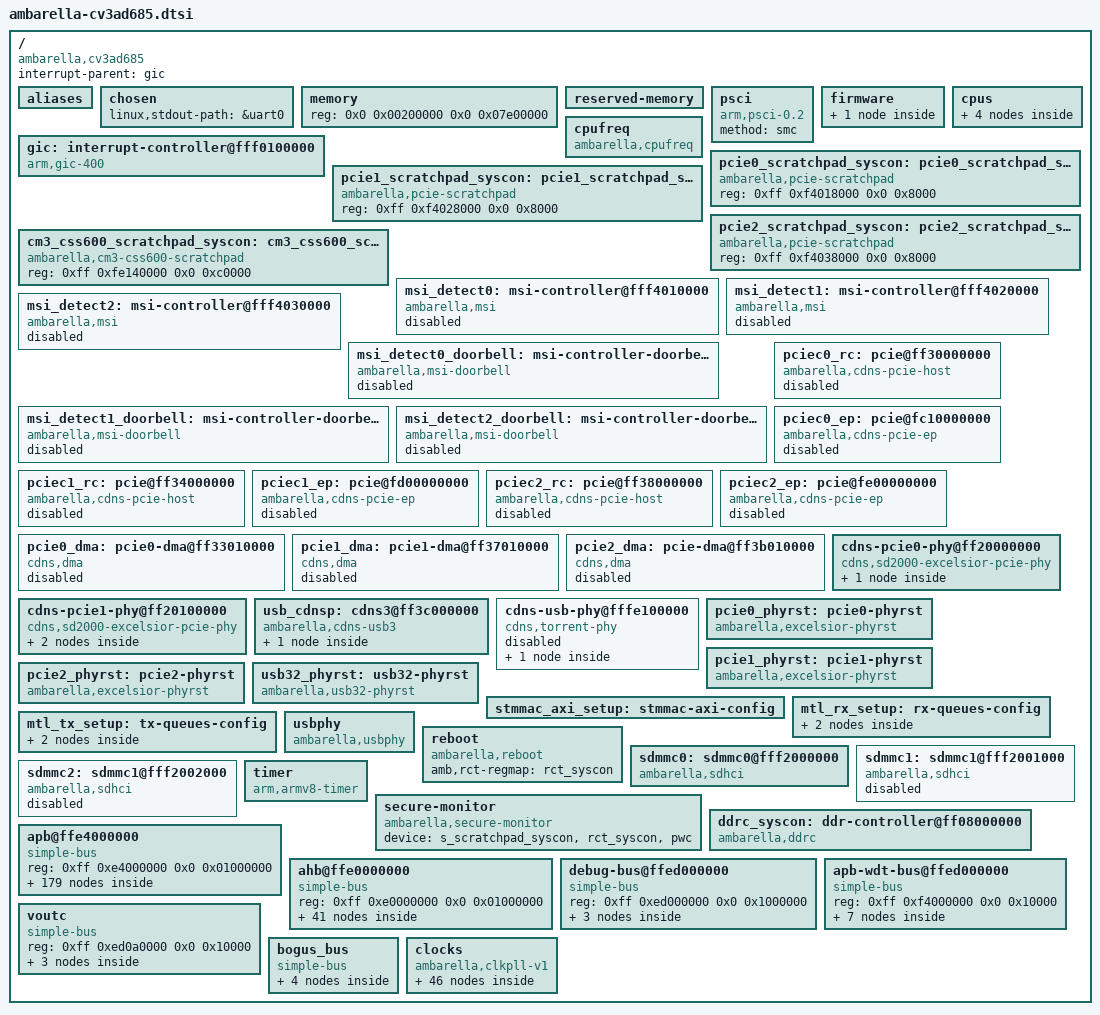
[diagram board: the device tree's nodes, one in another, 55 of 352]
/*
 * Copyright (C) 2013 Ambarella,Inc. - http://www.ambarella.com/
 * Author: Cao Rongrong <rrcao@ambarella.com>
 *
 * This program is free software; you can redistribute it and/or modify
 * it under the terms of the GNU General Public License version 2 as
 * published by the Free Software Foundation.
 */

/ {
	compatible = "ambarella,cv3ad685";
	interrupt-parent = <&gic>;
	#address-cells = <2>;
	#size-cells = <2>;

	aliases {
		serial0 = &uart0;
		serial1 = &uart1;
		serial2 = &uart2;
		serial3 = &uart3;
		serial4 = &uart4;
		nand = &nand0;
		sd0 = &sdmmc0;
		sd1 = &sdmmc1;
		sd2 = &sdmmc2;
		mmc0 = &sdmmc0;
		mmc1 = &sdmmc1;
		mmc2 = &sdmmc2;
		spinor = &spinor0;
		i2c0 = &i2c0;
		i2c1 = &i2c1;
		i2c2 = &i2c2;
		i2c3 = &i2c3;
		i2c4 = &i2c4;
		i2c5 = &i2c5;
		i2c6 = &i2c6;
		i2c7 = &i2c7;
		i2c8 = &i2c8;
		i2cs = &i2cs;
		spi0 = &spi0;
		spi1 = &spi1;
		spi2 = &spi2;
		spi3 = &spi3;
		spi4 = &spi4;
		spi5 = &spi5;
		spi6 = &spi6;
		spi7 = &spi7;
		ethernet0 = &mac0;
		ethernet1 = &mac1;
		ethernet2 = &mac2;
		dma0 = &dma0;
		dma1 = &dma1;
		dma2 = &dma2;
	};

	chosen: chosen {
		linux,stdout-path = &uart0;
	};

	/*
	 * the memory node will be overwritten in Amboot,
	 * here is just the default value.
	 */
	memory {
		device_type = "memory";
		reg = <0x0 0x00200000 0x0 0x07e00000>; /* 126M */
	};

	reserved-memory {
		#address-cells = <2>;
		#size-cells = <2>;
		ranges;
	};

	psci {
		compatible = "arm,psci-0.2";
		method = "smc";
	};

	firmware {
		optee {
			compatible = "linaro,optee-tz";
			method = "smc";
		};
	};

/*
	pmu {
		compatible = "arm,cortex-a78-pmu";
		interrupts = <0 3 0x4>,
			     <0 4 0x4>;
	};
*/

	cpus {
		#address-cells = <1>;
		#size-cells = <0>;

		cpu@0 {
			compatible = "arm,cortex-a78", "arm,armv8";
			device_type = "cpu";
			reg = <0x000>;
			enable-method = "psci";
		};

		cpu@1 {
			compatible = "arm,cortex-a78", "arm,armv8";
			device_type = "cpu";
			reg = <0x100>;
			enable-method = "psci";
		};

		cpu@2 {
			compatible = "arm,cortex-a78", "arm,armv8";
			device_type = "cpu";
			reg = <0x200>;
			enable-method = "psci";
		};

		cpu@3 {
			compatible = "arm,cortex-a78", "arm,armv8";
			device_type = "cpu";
			reg = <0x300>;
			enable-method = "psci";
		};
	};

	cpufreq {
		compatible = "ambarella,cpufreq";

		/*
		 * MASK
		 * + --- + ----- + ----- +
		 * | bit |   1   |   0   |
		 * + --- + ----- + ----- +
		 * | clk |  CORE | CORTEX|
		 * + --- + ----- + ----- +
		 */
		cpufreq-mask = <1>;
		amb,timer-freq-adjust-off;
		clocks = <&gclk_cortex &gclk_core>;
		clock-names = "cortex_clk", "core_clk";
		clocks-frequency-cortex-core =
			<1008000  504000>,
			<816000  336000>,
			<600000  240000>;
	};

	gic: interrupt-controller@fff0100000 {
		compatible = "arm,gic-400";
		#interrupt-cells = <3>;
		#address-cells = <0>;
		#size-cells = <1>;
		interrupt-controller;
		reg = <0xff 0xf0101000 0x0 0x1000>,	/* GIC Dist */
		      <0xff 0xf0102000 0x0 0x2000>,	/* GIC CPU */
		      /* following are not used if no virtulization */
		      <0xff 0xf0104000 0x0 0x2000>,	/* GIC VCPU Control */
		      <0xff 0xf0106000 0x0 0x2000>;	/* GIC VCPU */
		interrupts = <1 9 0xf04>;		/* GIC Maintenence IRQ */
	};

	pcie0_scratchpad_syscon: pcie0_scratchpad_syscon@fff4018000 {
		compatible = "ambarella,pcie-scratchpad", "syscon";
		reg = <0xff 0xf4018000 0x0 0x8000>;
	};

	pcie1_scratchpad_syscon: pcie1_scratchpad_syscon@fff4028000 {
		compatible = "ambarella,pcie-scratchpad", "syscon";
		reg = <0xff 0xf4028000 0x0 0x8000>;
	};

	pcie2_scratchpad_syscon: pcie2_scratchpad_syscon@fff4038000 {
		compatible = "ambarella,pcie-scratchpad", "syscon";
		reg = <0xff 0xf4038000 0x0 0x8000>;
	};

	cm3_css600_scratchpad_syscon: cm3_css600_scratchpad_syscon@fffe140000 {
		compatible = "ambarella,cm3-css600-scratchpad", "syscon";
		reg = <0xff 0xfe140000 0x0 0xc0000>;
	};

	msi_detect0: msi-controller@fff4010000 {
		compatible = "ambarella,msi";
		reg = <0xff 0xf4010000 0x0 0x08000>;
		msi-controller;
		msi-detection,spi-range = <257 4>;
		status = "disabled";
	};

	msi_detect1: msi-controller@fff4020000 {
		compatible = "ambarella,msi";
		reg = <0xff 0xf4020000 0x0 0x08000>;
		msi-controller;
		msi-detection,spi-range = <286 4>;
		status = "disabled";
	};

	msi_detect2: msi-controller@fff4030000 {
		compatible = "ambarella,msi";
		reg = <0xff 0xf4030000 0x0 0x08000>;
		msi-controller;
		msi-detection,spi-range = <315 4>;
		status = "disabled";
	};

	msi_detect0_doorbell: msi-controller-doorbell@fff4010000 {
		compatible = "ambarella,msi-doorbell";
		reg = <0xff 0xf4010000 0x0 0x08000>;
		msi-controller;
		msi-detection,spi-range = <257 4>;
		status = "disabled";
	};

	msi_detect1_doorbell: msi-controller-doorbell@fff4020000 {
		compatible = "ambarella,msi-doorbell";
		reg = <0xff 0xf4020000 0x0 0x08000>;
		msi-controller;
		msi-detection,spi-range = <286 4>;
		status = "disabled";
	};

	msi_detect2_doorbell: msi-controller-doorbell@fff4030000 {
		compatible = "ambarella,msi-doorbell";
		reg = <0xff 0xf4030000 0x0 0x08000>;
		msi-controller;
		msi-detection,spi-range = <315 4>;
		status = "disabled";
	};

	pciec0_rc: pcie@ff30000000 {
		compatible = "ambarella,cdns-pcie-host";
		device_type = "pci";
		#address-cells = <3>;
		#size-cells = <2>;
		#interrupt-cells = <1>;
		bus-range = <0 15>;
		linux,pci-domain = <0>;

		reg = <0xff 0x30000000 0x0 0x03006000>,
		      <0xfc 0x00000000 0x0 0x00100000>;	/* RC only */
		reg-names = "reg", "cfg";

		/*
		 * type: 0x01000000 IO
		 * type: 0x02000000 32bit mem space No prefetch
		 * type: 0x03000000 64bit mem space No prefetch
		 * type: 0x43000000 64bit mem space prefetch
		 */
		ranges = <0x02000000 0x00 0x00000000 0xfc 0x11000000 0x00 0x01000000>,
			 <0x43000000 0xfc 0x12000000 0xfc 0x12000000 0x00 0x08000000>;

		interrupt-map-mask = <0x00 0x0 0x0 0x7>;
		interrupt-map = <0x0 0x0 0x0 0x1 &gic 0 253 0x4>,
				<0x0 0x0 0x0 0x2 &gic 0 254 0x4>,
				<0x0 0x0 0x0 0x3 &gic 0 255 0x4>,
				<0x0 0x0 0x0 0x4 &gic 0 256 0x4>;

		cdns,no-bar-match-nbits = <40>;
		msi-parent = <&msi_detect0>;

		amb,scr-regmap = <&pcie0_scratchpad_syscon 0x14>;
		phys = <&pcie0_phy>;
		phy-names="pcie-phy";
		/* May be override by dts" */
		status = "disabled";
	};

	pciec0_ep: pcie@fc10000000 {
		compatible = "ambarella,cdns-pcie-ep";
		reg = <0xff 0x30000000 0x0 0x03020000>,
		      <0xfc 0x10000000 0x1 0x00000000>;
		reg-names = "reg", "mem";
		device_type = "pci-endpoint";

		cdns,max-outbound-regions = <8>;
		max-functions = /bits/ 8 <1>;

		amb,scr-regmap = <&pcie0_scratchpad_syscon 0x14>;
		phys = <&pcie0_phy>;
		phy-names="pcie-phy";
		msi-parent = <&msi_detect0_doorbell>;
		/* May be override by dts */
		status = "disabled";
	};

	pciec1_rc: pcie@ff34000000 {
		compatible = "ambarella,cdns-pcie-host";
		reg = <0xff 0x34000000 0x0 0x03006000>,
		      <0xfd 0x40000000 0x0 0x00100000>;
		reg-names = "reg", "cfg";
		device_type = "pci";
		#address-cells = <3>;
		#size-cells = <2>;
		#interrupt-cells = <1>;
		bus-range = <0 15>;
		linux,pci-domain = <1>;

		ranges = <0x02000000 0x00 0x00000000 0xfd 0x51000000 0x00 0x01000000>,
			 <0x43000000 0xfd 0x52000000 0xfd 0x52000000 0x00 0x08000000>;

		interrupt-map-mask = <0x00 0x0 0x0 0x7>;
		interrupt-map = <0x0 0x0 0x0 0x1 &gic 0 282 0x4>,
				<0x0 0x0 0x0 0x2 &gic 0 283 0x4>,
				<0x0 0x0 0x0 0x3 &gic 0 284 0x4>,
				<0x0 0x0 0x0 0x4 &gic 0 285 0x4>;

		cdns,no-bar-match-nbits = <40>;
		msi-parent = <&msi_detect0>;

		amb,scr-regmap = <&pcie1_scratchpad_syscon 0x14>;
		phys = <&pcie1_ln0_phy>;
		phy-names="pcie-phy";

		/* May be override by dts" */
		status = "disabled";
	};

	pciec1_ep: pcie@fd00000000 {
		compatible = "ambarella,cdns-pcie-ep";
		reg = <0xff 0x34000000 0x0 0x03020000>,
		      <0xfd 0x40000000 0x0 0x10000000>;
		reg-names = "reg", "mem";
		device_type = "pci-endpoint";

		cdns,max-outbound-regions = <8>;	/* EP only */
		max-functions = /bits/ 8 <1>;		/* EP only */

		amb,scr-regmap = <&pcie1_scratchpad_syscon 0x14>;
		phys = <&pcie1_ln0_phy>;
		phy-names="pcie-phy";
		msi-parent = <&msi_detect1_doorbell>;

		/* May be override by dts" */
		status = "disabled";
	};

	pciec2_rc: pcie@ff38000000 {
		compatible = "ambarella,cdns-pcie-host";
		reg = <0xff 0x38000000 0x0 0x03006000>,
		     <0xfe 0x40000000 0x0 0x00200000>;
		reg-names = "reg", "cfg";
		device_type = "pci";
		#address-cells = <3>;
		#size-cells = <2>;
		#interrupt-cells = <1>;
		bus-range = <0 15>;
		linux,pci-domain = <2>;

		/*
		* RC only, May be override by dts"
		*
		* type: 0x01000000 IO
		* type: 0x02000000 32bit mem space No prefetch
		* type: 0x03000000 64bit mem space No prefetch
		* type: 0x43000000 64bit mem space prefetch
		*/
		ranges = <0x02000000 0x00 0x00000000 0xfe 0x91000000 0x00 0x01000000>,
			 <0x43000000 0xfe 0x92000000 0xfe 0x92000000 0x00 0x08000000>;

		interrupt-map-mask = <0x00 0x0 0x0 0x7>;
		interrupt-map = <0x0 0x0 0x0 0x1 &gic 0 311 0x4>,
				<0x0 0x0 0x0 0x2 &gic 0 312 0x4>,
				<0x0 0x0 0x0 0x3 &gic 0 313 0x4>,
				<0x0 0x0 0x0 0x4 &gic 0 314 0x4>;

		cdns,no-bar-match-nbits = <40>;
		msi-parent = <&msi_detect0>;

		amb,scr-regmap = <&pcie2_scratchpad_syscon 0x14>;
		phys = <&pcie1_ln1_phy>;
		phy-names="pcie-phy";
		/* May be override by dts" */
		status = "disabled";
	};

	pciec2_ep: pcie@fe00000000 {
		compatible = "ambarella,cdns-pcie-ep";
		reg = <0xff 0x38000000 0x0 0x03020000>,
		     <0xfe 0x40000000 0x0 0x10000000>;
		reg-names = "reg", "mem";
		device_type = "pci-endpoint";

		cdns,max-outbound-regions = <8>;	/* EP only */
		max-functions = /bits/ 8 <1>;		/* EP only */

		amb,scr-regmap = <&pcie2_scratchpad_syscon 0x14>;
		phys = <&pcie1_ln1_phy>;
		phy-names="pcie-phy";
		msi-parent = <&msi_detect2_doorbell>;
		/* May be override by dts" */
		status = "disabled";
	};

	pcie0_dma: pcie0-dma@ff33010000 {
		compatible = "cdns,dma";
		reg = <0xff 0x33010000 0x0 0x00010000>;
		interrupts = <0 249 0x1>, <0 250 0x1>, <0 251 0x1>, <0 252 0x1>;
		/* May be override by dts */
		status = "disabled";
	};

	pcie1_dma: pcie1-dma@ff37010000 {
		compatible = "cdns,dma";
		reg = <0xff 0x37010000 0x0 0x00010000>;
		interrupts = <0 278 0x1>, <0 279 0x1>, <0 280 0x1>, <0 281 0x1>;
		/* May be override by dts */
		status = "disabled";
	};

	pcie2_dma: pcie-dma@ff3b010000 {
		compatible = "cdns,dma";
		reg = <0xff 0x3b010000 0x0 0x00010000>;
		interrupts = <0 307 0x1>, <0 308 0x1>, <0 309 0x1>, <0 310 0x1>;
		/* May be override by dts */
		status = "disabled";
	};

	/* This is a single-link PHY controller */
	cdns-pcie0-phy@ff20000000 {
		compatible = "cdns,sd2000-excelsior-pcie-phy";
		#address-cells = <1>;
		#size-cells = <0>;
		reg = <0xff 0x20000000 0x0 0x00100000>;

		resets = <&pcie0_phyrst 0>;
		reset-names = "phy_reset";

		clocks = <&cdns_phy_refclk>;
		clock-names = "refclk";

		pcie0_phy: phy@0 {
			reg = <0>;
			resets=<&pcie0_phyrst 2>;
			#phy-cells= <0>;
			cdns,num-lanes = <4>;
			cdns,ssc-mode = <0>;		// NO_SSC
			/* specify cdns,pcie-mode in dts, 1 is RC, 0 is EP */
			cdns,pcie-mode = <1>;
		};
	};

	/*
	 * This is a multi-link PHY controller, two lanes are assigned
	 * to two PCIe controllers seperately.
	 */
	cdns-pcie1-phy@ff20100000 {
		compatible = "cdns,sd2000-excelsior-pcie-phy";
		#address-cells = <1>;
		#size-cells = <0>;
		reg = <0xff 0x20100000 0x0 0x00100000>;

		resets = <&pcie1_phyrst 3>;
		reset-names = "phy_reset";

		clocks = <&cdns_phy_refclk>;
		clock-names = "refclk";

		pcie1_ln0_phy: phy@0 {
			reg = <0>;
			resets=<&pcie1_phyrst 5>;
			#phy-cells= <0>;
			cdns,num-lanes = <1>;
			cdns,ssc-mode = <0>;		// NO_SSC
			/* maybe override by dts, 1 is RC, 0 is EP */
			cdns,pcie-mode = <1>;
		};
		pcie1_ln1_phy: phy@1 {
			reg = <0>;
			resets=<&pcie2_phyrst 6>;
			#phy-cells= <0>;
			cdns,num-lanes = <1>;
			cdns,ssc-mode = <0>;		// NO_SSC
			/* maybe override by dts, 1 is RC, 0 is EP */
			cdns,pcie-mode = <0>;
		};
	};

	usb_cdnsp: cdns3@ff3c000000 {
		compatible = "ambarella,cdns-usb3";
		#address-cells = <2>;
		#size-cells = <2>;
		reg = <0xff 0x3c000000 0x0 0x1000000>;
		ranges;
		amb,scr-regmap = <&n_scratchpad_syscon>;
		amb,ocp-polarity = <1>;

		cdns3: cdns3 {
			compatible = "cdns,usb3";
			interrupts = <0 243 0x4>, <0 243 0x4>, <0 243 0x4>;
			interrupt-names = "host", "peripheral", "otg";
			reg = <0xff 0x3c008000 0x0 0x10000>,
			      <0xff 0x3c004000 0x0 0x4000>,
			      <0xff 0x3c000000 0x0 0x4000>;
			reg-names = "xhci", "dev", "otg";
			dr_mode = "otg";
			phys = <&usb32_phy>;
			phy-names = "cdns3,usb3-phy";
			maximum-speed = "super-speed-plus";
			usb-role-switch;
		};
	};

	cdns-usb-phy@fffe100000 {
		compatible = "cdns,torrent-phy";
		#address-cells = <1>;
		#size-cells = <0>;
		reg = <0xff 0xfe100000 0x0 0x00040000>;

		clocks = <&cdns_phy_refclk>;
		clock-names = "refclk";

		resets = <&usb32_phyrst 0>;
		reset-names = "torrent_reset";

		status = "disabled";

		usb32_phy: phy@0 {
			reg = <0>;
			resets = <&usb32_phyrst 1>;
			#phy-cells = <0>;
			cdns,phy-type = <4>;	/* TYPE_USB */
			cdns,num-lanes = <2>;
			cdns,ssc-mode = <2>;	/* INTERNAL_SSC */
		};
	};

	pcie0_phyrst: pcie0-phyrst {
		compatible = "ambarella,excelsior-phyrst";
		#reset-cells = <1>;
		amb,scr-regmap = <&n_scratchpad_syscon 0x180 0x190>;
		amb,pcie-scr-regmap = <&pcie0_scratchpad_syscon 0x4 0x8>;
		amb,pcie-controller = <&pciec0_rc>;
		amb,pcie-phy-id = <0>;
		amb,pcie-gen = <5>;
	};

	pcie1_phyrst: pcie1-phyrst {
		compatible = "ambarella,excelsior-phyrst";
		#reset-cells = <1>;
		amb,scr-regmap = <&n_scratchpad_syscon 0x184 0x190>;
		amb,pcie-scr-regmap = <&pcie1_scratchpad_syscon 0x4 0x8>;
		amb,pcie-controller = <&pciec1_rc>;
		amb,pcie-phy-id = <1>;
		amb,pcie-gen = <5>;
	};

	pcie2_phyrst: pcie2-phyrst {
		compatible = "ambarella,excelsior-phyrst";
		#reset-cells = <1>;
		amb,scr-regmap = <&n_scratchpad_syscon 0x184 0x190>;
		amb,pcie-scr-regmap = <&pcie2_scratchpad_syscon 0x4 0x8>;
		amb,pcie-controller = <&pciec2_ep>;
		amb,pcie-phy-id = <1>;
		amb,pcie-gen = <5>;
	};

	usb32_phyrst: usb32-phyrst {
		compatible = "ambarella,usb32-phyrst";
		#reset-cells = <1>;
		amb,scr-regmap = <&n_scratchpad_syscon 0x154 0x174 0x16c>;
	};


	stmmac_axi_setup: stmmac-axi-config {
		/* enable IS_ENABLED(CONFIG_ARCH_DMA_ADDR_T_64BIT) to enable 40bits dma
		   descriptor must be within 4GB.  buffer-addr can be 40bit
		 */
		snps,wr_osr_lmt = <0x3>;		/* cv3:max 8 Ref DMA_SysBus_Mode */
		snps,rd_osr_lmt = <0x3>;		/* cv3:max 8 Ref DMA_SysBus_Mode */
		snps,blen = <256 128 64 32 0 0 0>;	/* when FB=0,last 3 item has no mean */
	};

	/* at least two different queues to enable FPE features */
	mtl_rx_setup: rx-queues-config {
		snps,rx-queues-to-use = <2>;
		snps,rx-sched-sp;

		queue0 {
			snps,dcb-algorithm;
			snps,route-multi-broad;
			snps,map-to-dma-channel = <0x0>;
			snps,priority = <0x0>;
		};
		queue1 {
			snps,avb-algorithm;
			snps,route-avcp;
			snps,map-to-dma-channel = <0x1>;
			snps,priority = <0x1>;
		};
	};

	mtl_tx_setup: tx-queues-config {
		snps,tx-queues-to-use = <2>;
		snps,tx-sched-sp;

		queue0 {
			snps,dcb-algorithm;
			snps,weight = <0x10>;
			snps,priority = <0x0>;
		};
		queue1 {
			snps,avb-algorithm;
			snps,send_slope = <0x1000>;
			snps,idle_slope = <0x1000>;
			snps,high_credit = <0x04000000>; /* assume AVBframe = 8192 (8192*8*1024) */
			snps,low_credit = <0x18000000>;	 /* assume AVBframe = 8192 (8192*2*8*1024) of 2complete */
			snps,priority = <0x1>;
		};
	};

	usbphy: usbphy {
		compatible = "ambarella,usbphy";
		amb,ana-regmap = <&rct_syscon 0x050>;
		amb,own-regmap = <&rct_syscon 0x2c0>;		/* TODO: no such register in RCT */
		amb,phy-regmap = <&n_scratchpad_syscon 0x118>;
		amb,pol-regmap = <&n_scratchpad_syscon 0x060>;	/* TODO: polarity is remvoed in CV5 */
		amb,host-phy-num = <1>;
		amb,ocp-polarity = <0>;
	};

	reboot {
		compatible = "ambarella,reboot";
		amb,rct-regmap = <&rct_syscon>;
	};

	sdmmc0: sdmmc0@fff2000000 {
		compatible = "ambarella,sdhci";
		reg = <0xff 0xf2000000 0x0 0x1000>;
		interrupts = <0 138 0x4>;
		clocks = <&gclk_sd0>;
		bus-width = <8>;
		cap-sdio-irq;
		cap-sd-highspeed;
		cap-mmc-highspeed;
		mmc-hs200-1_8v;
	};

	sdmmc1: sdmmc1@fff2001000 { /* SDIO0 */
		compatible = "ambarella,sdhci";
		reg = <0xff 0xf2001000 0x0 0x1000>;
		interrupts = <0 139 0x4>;
		clocks = <&gclk_sd1>;
		bus-width = <4>;
		cap-sdio-irq;
		cap-sd-highspeed;
		cap-mmc-highspeed;
		status = "disabled";
	};

	sdmmc2: sdmmc1@fff2002000 { /* SDIO1 */
		compatible = "ambarella,sdhci";
		reg = <0xff 0xf2002000 0x0 0x1000>;
		interrupts = <0 140 0x4>;
		clocks = <&gclk_sd2>;
		bus-width = <4>;
		cap-sdio-irq;
		cap-sd-highspeed;
		cap-mmc-highspeed;
		status = "disabled";
	};

	timer {
		compatible = "arm,armv8-timer";
		interrupts = <1 13 0xf08>,	/* Secure Phys IRQ */
			     <1 14 0xf08>,	/* Non-secure Phys IRQ */
			     <1 11 0xf08>,	/* Virt IRQ */
			     <1 10 0xf08>;	/* Hyp IRQ */
	};

	secure-monitor {
		compatible = "ambarella,secure-monitor";
		#address-cells = <1>;
		#size-cells = <0>;
		device = <&s_scratchpad_syscon &rct_syscon &pwc>;
	};

	ddrc_syscon:ddr-controller@ff08000000 {
		compatible = "ambarella,ddrc", "syscon";
		#address-cells = <1>;
		#size-cells = <1>;
		reg = <0xff 0x08000000 0x0 0x80000>;
		burst-size = <0>;		/* This property will be overwritten in AMBOOT. */
	};

	apb@ffe4000000 {
		compatible = "simple-bus";
		#address-cells = <1>;
		#size-cells = <1>;
		reg = <0xff 0xe4000000 0x0 0x01000000>;
		ranges = <0xe4000000 0xff 0xe4000000 0x01000000>;

		clocksource1: timer@e4004054 {	/* timer6 */
			compatible = "ambarella,clock-source";
			reg = <0xe4004054 0x10 0xe4004030 0x4>;
			interrupts = <0 158 0x1>;
			ctrl-offset = <20>; /* bit offset in timer-ctrl reg */
			clocks = <&gclk_apb>;
			status = "disabled";
		};

		clockevent1: timer@e4004064 {	/* timer7, timer8, timer9, timer10 */
			compatible = "ambarella,local-clock-event";
			reg = <0xe4004064 0x10 0xe4004030 0x4>,
			      <0xe4004074 0x10 0xe4004030 0x4>,
			      <0xe4004088 0x10 0xe4004084 0x4>,
			      <0xe4004098 0x10 0xe4004084 0x4>;
			interrupts = <0 159 0x1>, <0 160 0x1>, <0 161 0x1>, <0 162 0x1>;
			ctrl-offset = <24 28 00 04>; /* bit offset in timer-ctrl reg */
			clocks = <&gclk_apb>;
			status = "disabled";
		};

		clocksource2: timer@e4005054 {	/* timer16 */
			compatible = "ambarella,clock-source";
			reg = <0xe4005054 0x10 0xe4005030 0x4>;
			interrupts = <0 168 0x1>;
			ctrl-offset = <20>; /* bit offset in timer-ctrl reg */
			clocks = <&gclk_apb>;
			status = "disabled";
		};

		clockevent2: timer@e4005064 {	/* timer17, timer18, timer19, timer20 */
			compatible = "ambarella,local-clock-event";
			reg = <0xe4005064 0x10 0xe4005030 0x4>,
			      <0xe4005074 0x10 0xe4005030 0x4>,
			      <0xe4005088 0x10 0xe4005084 0x4>,
			      <0xe4005098 0x10 0xe4005084 0x4>;
			interrupts = <0 169 0x1>, <0 170 0x1>, <0 171 0x1>, <0 172 0x1>;
			ctrl-offset = <24 28 00 04>; /* bit offset in timer-ctrl reg */
			clocks = <&gclk_apb>;
			status = "disabled";
		};

		clocksource3: timer@e4006054 {	/* timer26 */
			compatible = "ambarella,clock-source";
			reg = <0xe4006054 0x10 0xe4006030 0x4>;
			interrupts = <0 464 0x1>;
			ctrl-offset = <20>; /* bit offset in timer-ctrl reg */
			clocks = <&gclk_apb>;
			status = "disabled";
		};

		clockevent3: timer@e4006044 {	/* timer27, timer28, timer29, timer30 */
			compatible = "ambarella,local-clock-event";
			reg = <0xe4006064 0x10 0xe4006030 0x4>,
			      <0xe4006074 0x10 0xe4006030 0x4>,
			      <0xe4006088 0x10 0xe4006084 0x4>,
			      <0xe4006098 0x10 0xe4006084 0x4>;
			interrupts = <0 465 0x1>, <0 466 0x1>, <0 467 0x1>, <0 468 0x1>;
			ctrl-offset = <24 28 00 04>; /* bit offset in timer-ctrl reg */
			clocks = <&gclk_apb>;
			status = "disabled";
		};

		uart0: uart@e4000000 {
			compatible = "ambarella,uart";
			reg = <0xe4000000 0x1000>;
			interrupts = <0 241 0x4>;
			pinctrl-names = "default";
			pinctrl-0 = <&uart0_pins>;
			clocks = <&gclk_uart0>;
			status = "ok";
		};

		ir@e4001000 {
			compatible = "ambarella,ir";
			reg = <0xe4001000 0x1000>;
			interrupts = <0 242 0x4>;
			pinctrl-names = "default";
			pinctrl-0 = <&ir_pins_a>;
			clocks = <&gclk_ir>;
			status = "disabled";
		};

		i2c0: i2c@e4008000 {
			compatible = "ambarella,i2c";
			#address-cells = <1>;
			#size-cells = <0>;
			reg = <0xe4008000 0x1000>;
			interrupts = <0 214 0x4>;
			pinctrl-names = "default";
			pinctrl-0 = <&i2c0_pins_a>;
			clocks = <&gclk_apb>;
			clock-frequency = <100000>;
			amb,i2c-class = <0x81>;
			status = "disabled";
		};

		i2c1: i2c@e4009000 {
			compatible = "ambarella,i2c";
			#address-cells = <1>;
			#size-cells = <0>;
			reg = <0xe4009000 0x1000>;
			interrupts = <0 215 0x4>;
			pinctrl-names = "default";
			pinctrl-0 = <&i2c1_pins_a>;
			clocks = <&gclk_apb>;
			clock-frequency = <100000>;
			amb,i2c-class = <0x08>;
			status = "disabled";
		};

		i2c2: i2c@e400a000 {
			compatible = "ambarella,i2c";
			#address-cells = <1>;
			#size-cells = <0>;
			reg = <0xe400a000 0x1000>;
			interrupts = <0 216 0x4>;
			clocks = <&gclk_apb>;
			pinctrl-names = "default";
			pinctrl-0 = <&i2c2_pins_a>;
			clock-frequency = <100000>;
			amb,i2c-class = <0x81>;
			status = "disabled";
		};

		i2c3: i2c@e400b000 {
			compatible = "ambarella,i2c";
			#address-cells = <1>;
			#size-cells = <0>;
			reg = <0xe400b000 0x1000>;
			interrupts = <0 217 0x4>;
			clocks = <&gclk_apb>;
			pinctrl-names = "default";
			pinctrl-0 = <&i2c3_pins_a>;
			clock-frequency = <100000>;
			amb,i2c-class = <0x81>;
			status = "disabled";
		};

		i2c4: i2c@e400e000 {
			compatible = "ambarella,i2c";
			#address-cells = <1>;
			#size-cells = <0>;
			reg = <0xe400e000 0x1000>;
			interrupts = <0 218 0x4>;
			clocks = <&gclk_apb>;
			pinctrl-names = "default";
			pinctrl-0 = <&i2c4_pins_a>;
			clock-frequency = <100000>;
			amb,i2c-class = <0x81>;
			status = "disabled";
		};

		i2c5: i2c@e400f000 {
			compatible = "ambarella,i2c";
			#address-cells = <1>;
			#size-cells = <0>;
			reg = <0xe400f000 0x1000>;
			interrupts = <0 219 0x4>;
			clocks = <&gclk_apb>;
			pinctrl-names = "default";
			pinctrl-0 = <&i2c5_pins_a>;
			clock-frequency = <100000>;
			amb,i2c-class = <0x81>;
			status = "disabled";
		};

		i2c6: i2c@e401c000 {
			compatible = "ambarella,i2c";
			#address-cells = <1>;
			#size-cells = <0>;
			reg = <0xe401c000 0x1000>;
			interrupts = <0 220 0x4>;
			clocks = <&gclk_apb>;
			pinctrl-names = "default";
			pinctrl-0 = <&i2c6_pins_a>;
			clock-frequency = <100000>;
			amb,i2c-class = <0x81>;
			status = "disabled";
		};

		i2c7: i2c@e401d000 {
			compatible = "ambarella,i2c";
			#address-cells = <1>;
			#size-cells = <0>;
			reg = <0xe401d000 0x1000>;
			interrupts = <0 221 0x4>;
			clocks = <&gclk_apb>;
			pinctrl-names = "default";
			pinctrl-0 = <&i2c7_pins_a>;
			clock-frequency = <100000>;
			amb,i2c-class = <0x81>;
			status = "disabled";
		};

		i2c8: i2c@e401e000 {
			compatible = "ambarella,i2c";
			#address-cells = <1>;
			#size-cells = <0>;
			reg = <0xe401e000 0x1000>;
			interrupts = <0 222 0x4>;
			clocks = <&gclk_apb>;
			pinctrl-names = "default";
			pinctrl-0 = <&i2c8_pins_a>;
			clock-frequency = <100000>;
			amb,i2c-class = <0x81>;
			status = "disabled";
		};

		i2cs: i2cs@e4007000 {
			compatible = "ambarella,i2cs";
			#address-cells = <1>;
			#size-cells = <0>;
			reg = <0xe4007000 0x1000>;
			interrupts = <0 223 0x4>;
			clocks = <&gclk_apb>;
			pinctrl-names = "default";
			pinctrl-0 = <&i2cs0_pins>;
			status = "disabled";
		};

		pwm0: pwm@e4003000 {
			compatible = "ambarella,pwm";
			reg = <0xe4003000 0x1000>;
			clock-frequency = <2000000>;
			clocks = <&gclk_pwm>;
			#pwm-cells = <3>;
		};

		pwm1: pwm@e400c000 {
			compatible = "ambarella,pwm";
			reg = <0xe400c000 0x1000>;
			clock-frequency = <2000000>;
			clocks = <&gclk_pwm>;
			#pwm-cells = <3>;
		};

		pwm2: pwm@e400d000 {
			compatible = "ambarella,pwm";
			reg = <0xe400d000 0x1000>;
			clock-frequency = <2000000>;
			clocks = <&gclk_pwm>;
			#pwm-cells = <3>;
		};

		pinctrl: pinctrl@e4010000 {
			compatible = "ambarella,pinctrl";
			#address-cells = <1>;
			#size-cells = <0>;
			reg = <0xe4013000 0x1000>,
			      <0xe4014000 0x1000>,
			      <0xe4015000 0x1000>,
			      <0xe4016000 0x1000>,
			      <0xe4017000 0x1000>,
			      <0xe4018000 0x1000>,
			      <0xe4019000 0x1000>,
			      <0xe4010000 0x1000>;
			reg-names = "gpio0", "gpio1", "gpio2", "gpio3", "gpio4", "gpio5", "gpio6", "iomux";
			interrupts = <0 224 0x4>, <0 225 0x4>, <0 226 0x4>, <0 227 0x4>,
				     <0 228 0x4>, <0 229 0x4>, <0 230 0x4>;
			amb,pull-regmap = <&s_scratchpad_syscon>;
			amb,ds-regmap = <&rct_syscon 0x314>;
			amb,secure-ctrl-bit = <50 51 52 53 54 59 37 48>;

			gpio: gpio@0 {
				reg = <0>;
				gpio-controller;
				#gpio-cells = <2>;
				gpio-ranges = <&pinctrl 0 0 213>;
				interrupt-controller;
				#interrupt-cells = <2>;
			};

			uart0_pins: uart0@0 {
				reg = <0>;
				amb,pinmux-ids = <0x104b 0x104c>;
			};

			uart1_pins_a: uart1@0 {		/* UART0_AHB_TX/RX */
				reg = <0>;
				amb,pinmux-ids = <0x2017 0x2018>;
			};

			uart1_pins_b: uart1@1 {
				reg = <1>;
				amb,pinmux-ids = <0x2027 0x2028>;
			};

			uart1_pins_c: uart1@2 {
				reg = <2>;
				amb,pinmux-ids = <0x3043 0x3047>;
			};

			uart1_pins_d: uart1@3 {
				reg = <3>;
				amb,pinmux-ids = <0x10ac 0x10ad>;
			};

			uart1_pins_e: uart1@4 {
				reg = <4>;
				amb,pinmux-ids = <0x30bc 0x30bd>;
			};

			uart1_flow_pins_a: uart1_flow@0 {
				reg = <0>;
				amb,pinmux-ids = <0x2019 0x201a>;
			};

			uart1_flow_pins_b: uart1_flow@1 {
				reg = <1>;
				amb,pinmux-ids = <0x2029 0x202a>;
			};

			uart1_flow_pins_c: uart1_flow@2 {
				reg = <2>;
				amb,pinmux-ids = <0x3045 0x3048>;
			};

			uart1_flow_pins_d: uart1_flow@3 {
				reg = <3>;
				amb,pinmux-ids = <0x10ae 0x10af>;
			};

			uart1_flow_pins_e: uart1_flow@4 {
				reg = <4>;
				amb,pinmux-ids = <0x30be 0x30bf>;
			};

			uart2_pins_a: uart2@0 {		/* UART1_AHB_RX/RX */
				reg = <0>;
				amb,pinmux-ids = <0x201b 0x201c>;
			};

			uart2_pins_b: uart2@1 {
				reg = <1>;
				amb,pinmux-ids = <0x202b 0x202c>;
			};

			uart2_pins_c: uart2@2 {
				reg = <2>;
				amb,pinmux-ids = <0x10b0 0x10b1>;
			};

			uart2_pins_d: uart2@3 {
				reg = <3>;
				amb,pinmux-ids = <0x30b8 0x30b9>;
			};

			uart2_flow_pins_a: uart2_flow@0 {
				reg = <0>;
				amb,pinmux-ids = <0x201d 0x201e>;
			};

			uart2_flow_pins_b: uart2_flow@1 {
				reg = <1>;
				amb,pinmux-ids = <0x202d 0x202e>;
			};

			uart2_flow_pins_c: uart2_flow@2 {
				reg = <2>;
				amb,pinmux-ids = <0x10b2 0x10b3>;
			};

			uart2_flow_pins_d: uart2_flow@3 {
				reg = <3>;
				amb,pinmux-ids = <0x30ba 0x30bb>;
			};

			uart3_pins_a: uart3@0 {		/* UART2_AHB_RX/RX */
				reg = <0>;
				amb,pinmux-ids = <0x201f 0x2020>;
			};

			uart3_pins_b: uart3@1 {
				reg = <1>;
				amb,pinmux-ids = <0x202f 0x2030>;
			};

			uart3_pins_c: uart3@2 {
				reg = <2>;
				amb,pinmux-ids = <0x10b4 0x10b5>;
			};

			uart3_pins_d: uart3@3 {
				reg = <3>;
				amb,pinmux-ids = <0x30c0 0x30c1>;
			};

			uart3_flow_pins_a: uart3_flow@0 {
				reg = <0>;
				amb,pinmux-ids = <0x2021 0x2022>;
			};

			uart3_flow_pins_b: uart3_flow@1 {
				reg = <1>;
				amb,pinmux-ids = <0x2031 0x2032>;
			};

			uart3_flow_pins_c: uart3_flow@2 {
				reg = <2>;
				amb,pinmux-ids = <0x10b6 0x10b7>;
			};

			uart3_flow_pins_d: uart3_flow@3 {
				reg = <3>;
				amb,pinmux-ids = <0x30c2 0x30c3>;
			};

			uart4_pins_a: uart4@0 {		/* UART3_AHB_RX/RX */
				reg = <0>;
				amb,pinmux-ids = <0x2023 0x2024>;
			};

			uart4_pins_b: uart4@1 {
				reg = <1>;
				amb,pinmux-ids = <0x2033 0x2034>;
			};

			uart4_pins_c: uart4@2 {
				reg = <2>;
				amb,pinmux-ids = <0x30b4 0x30b5>;
			};

			uart4_flow_pins_a: uart4_flow@0 {
				reg = <0>;
				amb,pinmux-ids = <0x2025 0x2026>;
			};

			uart4_flow_pins_b: uart4_flow@1 {
				reg = <1>;
				amb,pinmux-ids = <0x2035 0x2036>;
			};

			uart4_flow_pins_c: uart4_flow@2 {
				reg = <2>;
				amb,pinmux-ids = <0x30b6 0x30b7>;
			};

			snand_pins: snand@0 {
				reg = <0>;
				amb,pinmux-ids = <0x1087 0x1088 0x1089 0x108a
						  0x108b 0x108c>;
			};

			spinor_pins: spinor@0 {
				reg = <0>;
				amb,pinmux-ids = <0x108d 0x108e 0x108f 0x1090
						  0x1091 0x1092 0x1093 0x1094
						  0x1095 0x1096 0x1097>;
			};

			sdmmc0_reset_pin: sdmmc0_reset@0 {
				reg = <0>;
				amb,pinmux-ids = <0x109f>;
			};

			sdmmc1_reset_pin: sdmmc1_reset@0 {
				reg = <0>;
				amb,pinmux-ids = <0x10a1>;
			};

			sdmmc2_reset_pin: sdmmc2_reset@0 {
				reg = <0>;
				amb,pinmux-ids = <0x10a3>;
			};

			enet_ext_osc_clk: enet-ext-osc-clk@0 {	/* shared by enet0/1/2 125MHZ input refclock */
				reg = <0>;
				amb,pinmux-ids = <0x2067>;
			};

			enet_2nd_ref_clk_a: enet-2nd-ref-clk@0 {
				reg = <0>;
				amb,pinmux-ids = <0x1066>;
			};

			enet_2nd_ref_clk_b: enet-2nd-ref-clk@1 {
				reg = <1>;
				amb,pinmux-ids = <0x1068>;
			};

			enet_2nd_ref_clk_c: enet-2nd-ref-clk@2 {
				reg = <2>;
				amb,pinmux-ids = <0x2068>;
			};

			enet_2nd_ref_clk_d: enet-2nd-ref-clk@3 {
				reg = <3>;
				amb,pinmux-ids = <0x1077>;
			};

			rgmii0_pins: eth0@0 {	/* ethernet-mac0 && use mac-mdio */
				reg = <0>;
				amb,pinmux-ids = <0x2058 0x2059 0x205a 0x205b
						  0x205c 0x205d 0x205e 0x205f
						  0x2060 0x2061	0x2062 0x2063 /* eth-mdio */
						  0x2065 0x2066>;
			};

			rmii0_pins: eth0@1 {
				reg = <1>;
				amb,pinmux-ids = <0x1058 0x1059 0x105a 0x105d
						  0x105e 0x1061 0x1062 0x1063
						  0x1065>;
			};

			rgmii0_ptp_pps_o: enet0-ptp-pps-o@0 {
				reg = <0>;
				amb,pinmux-ids = <0x2064>;
			};

			rmii0_ptp_pps_o: enet0-ptp-pps-o@1 {
				reg = <1>;
				amb,pinmux-ids = <0x1064>;
			};

			rgmii1_pins: eth1@0 {	/* ethernet-mac1 */
				reg = <0>;
				amb,pinmux-ids = <0x2069 0x206a 0x206b 0x206c
						  0x206d 0x206e 0x206f 0x2070
						  0x2071 0x2072 0x2073 0x2074
						  0x2076 0x2077>;

			};

			rmii1_pins: eth1@1 {
				reg = <1>;
				amb,pinmux-ids = <0x1069 0x106a 0x106b 0x106e
						  0x106f 0x1072 0x2073 0x2074
						  0x1076>;
			};

			rgmii1_ptp_pps_o: enet1-ptp-pps-o@0 {
				reg = <0>;
				amb,pinmux-ids = <0x2075>;
			};

			rmii1_ptp_pps_o: enet1-ptp-pps-o@1 {
				reg = <1>;
				amb,pinmux-ids = <0x1075>;
			};

			rgmii2_pins: eth2@0 {	/* ethernet-mac2 */
				reg = <0>;
				amb,pinmux-ids = <0x2078 0x2079 0x207a 0x207b
						  0x207c 0x207d 0x207e 0x207f
						  0x2080 0x2081 0x2082 0x2083
						  0x2085 0x2086>;
			};

			rmii2_pins: eth2@1 {
				reg = <1>;
				amb,pinmux-ids = <0x1078 0x1079 0x107a 0x107d
						  0x107e 0x1081 0x1082 0x1083
						  0x1085>;
			};

			rgmii2_ptp_pps_o: enet2-ptp-pps-o@0 {
				reg = <0>;
				amb,pinmux-ids = <0x2084>;
			};

			rmii2_ptp_pps_o: enet2-ptp-pps-o@1 {
				reg = <1>;
				amb,pinmux-ids = <0x1084>;
			};

			i2c0_pins_a: i2c0@0 {
				reg = <0>;
				amb,pinmux-ids = <0x2002 0x2003>;
			};

			i2c0_pins_b: i2c0@1 {
				reg = <1>;
				amb,pinmux-ids = <0x1027 0x1028>;
			};

			i2c1_pins_a: i2c1@0 {
				reg = <0>;
				amb,pinmux-ids = <0x2004 0x2005>;
			};

			i2c1_pins_b: i2c1@1 {
				reg = <1>;
				amb,pinmux-ids = <0x1029 0x102a>;
			};

			i2c2_pins_a: i2c2@0 {
				reg = <0>;
				amb,pinmux-ids = <0x2007 0x2008>;
			};

			i2c2_pins_b: i2c2@1 {
				reg = <1>;
				amb,pinmux-ids = <0x102b 0x102c>;
			};

			i2c2_pins_c: i2c2@2 {
				reg = <2>;
				amb,pinmux-ids = <0x10a7 0x10a8>;
			};

			i2c3_pins_a: i2c3@0 {
				reg = <0>;
				amb,pinmux-ids = <0x2009 0x200a>;
			};

			i2c3_pins_b: i2c3@1 {
				reg = <1>;
				amb,pinmux-ids = <0x102d 0x102e>;
			};

			i2c4_pins_a: i2c4@0 {
				reg = <0>;
				amb,pinmux-ids = <0x200b 0x200c>;
			};

			i2c4_pins_b: i2c4@1 {
				reg = <1>;
				amb,pinmux-ids = <0x102f 0x1030>;
			};

			i2c5_pins_a: i2c5@0 {
				reg = <0>;
				amb,pinmux-ids = <0x200d 0x200e>;
			};

			i2c5_pins_b: i2c5@1 {
				reg = <1>;
				amb,pinmux-ids = <0x1031 0x1032>;
			};

			i2c6_pins_a: i2c6@0 {
				reg = <0>;
				amb,pinmux-ids = <0x200f 0x2010>;
			};

			i2c6_pins_b: i2c6@1 {
				reg = <1>;
				amb,pinmux-ids = <0x1033 0x1034>;
			};

			i2c7_pins_a: i2c7@0 {
				reg = <0>;
				amb,pinmux-ids = <0x2011 0x2012>;
			};

			i2c7_pins_b: i2c7@1 {
				reg = <1>;
				amb,pinmux-ids = <0x1035 0x1036>;
			};

			i2c8_pins_a: i2c8@0 {
				reg = <0>;
				amb,pinmux-ids = <0x2013 0x2014>;
			};

			i2c8_pins_b: i2c8@1 {
				reg = <1>;
				amb,pinmux-ids = <0x3033 0x3034>;
			};

			i2c8_pins_c: i2c8@2 {
				reg = <2>;
				amb,pinmux-ids = <0x1037 0x1038>;
			};

			i2cs0_pins: i2cs0@0 {
				reg = <0>;
				amb,pinmux-ids = <0x1039 0x103a>;
			};

			can0_pins_a: can0@0 {
				reg = <0>;
				amb,pinmux-ids = <0x10b8 0x10b9>;
			};

			can0_pins_b: can0@1 {
				reg = <1>;
				amb,pinmux-ids = <0x40ac 0x40ad>;
			};

			can1_pins_a: can1@0 {
				reg = <0>;
				amb,pinmux-ids = <0x10ba 0x10bb>;
			};

			can1_pins_b: can1@1 {
				reg = <1>;
				amb,pinmux-ids = <0x40ae 0x40af>;
			};

			can2_pins_a: can2@0 {
				reg = <0>;
				amb,pinmux-ids = <0x10bc 0x10bd>;
			};

			can2_pins_b: can2@1 {
				reg = <1>;
				amb,pinmux-ids = <0x40b0 0x40b1>;
			};

			can3_pins_a: can3@0 {
				reg = <0>;
				amb,pinmux-ids = <0x10be 0x10bf>;
			};

			can3_pins_b: can3@1 {
				reg = <1>;
				amb,pinmux-ids = <0x40b2 0x40b3>;
			};

			can4_pins_a: can4@0 {
				reg = <0>;
				amb,pinmux-ids = <0x10c0 0x10c1>;
			};

			can4_pins_b: can4@1 {
				reg = <1>;
				amb,pinmux-ids = <0x40b4 0x40b5>;
			};

			can5_pins_a: can5@0 {
				reg = <0>;
				amb,pinmux-ids = <0x10c2 0x10c3>;
			};

			can5_pins_b: can5@1 {
				reg = <1>;
				amb,pinmux-ids = <0x40b6 0x40b7>;
			};

			ir_pins_a: ir0@0 {
				reg = <0>;
				amb,pinmux-ids = <0x1000>;
			};

			ir_pins_b: ir0@1 {
				reg = <1>;
				amb,pinmux-ids = <0x30a6>;
			};

			wdt_pins_a: wdt0@0 {
				reg = <0>;
				amb,pinmux-ids = <0x2000>;
			};

			wdt_pins_b: wdt0@1 {
				reg = <1>;
				amb,pinmux-ids = <0x2001>;
			};

			wdt_pins_c: wdt0@2 {
				reg = <2>;
				amb,pinmux-ids = <0x2006>;
			};

			wdt_pins_d: wdt0@3 {
				reg = <3>;
				amb,pinmux-ids = <0x2015>;
			};

			wdt_pins_e: wdt0@4 {
				reg = <4>;
				amb,pinmux-ids = <0x20a9>;
			};

			wdt_pins_f: wdt0@5 {
				reg = <5>;
				amb,pinmux-ids = <0x30b3>;
			};

			i2s0_pins: i2s0@0 {
				reg = <0>;
				amb,pinmux-ids = <0x1050 0x1051 0x1052 0x1053>;
			};

			i2s1_pins: i2s1@0 {
				reg = <0>;
				amb,pinmux-ids = <0x1054 0x1055 0x1056 0x1057>;
			};

			dmic0_pins: dmic_pins@0 {
				reg = <0>;
				amb,pinmux-ids = <0x2050 0x2051>;
			};

			pwm0_pins_a: pwm0@0 {
				reg = <0>;
				amb,pinmux-ids = <0x3002>;
			};

			pwm0_pins_b: pwm0@1 {
				reg = <1>;
				amb,pinmux-ids = <0x3027>;
			};

			pwm0_pins_c: pwm0@2 {
				reg = <2>;
				amb,pinmux-ids = <0x203b>;
			};

			pwm0_pins_d: pwm0@3 {
				reg = <3>;
				amb,pinmux-ids = <0x104d>;
			};

			pwm1_pins_a: pwm1@0 {
				reg = <0>;
				amb,pinmux-ids = <0x3002>;
			};

			pwm1_pins_b: pwm1@1 {
				reg = <1>;
				amb,pinmux-ids = <0x3028>;
			};

			pwm1_pins_c: pwm1@2 {
				reg = <2>;
				amb,pinmux-ids = <0x203c>;
			};

			pwm1_pins_d: pwm1@3 {
				reg = <3>;
				amb,pinmux-ids = <0x104e>;
			};

			pwm2_pins_a: pwm2@0 {
				reg = <0>;
				amb,pinmux-ids = <0x3004>;
			};

			pwm2_pins_b: pwm2@1 {
				reg = <1>;
				amb,pinmux-ids = <0x3029>;
			};

			pwm2_pins_c: pwm2@2 {
				reg = <2>;
				amb,pinmux-ids = <0x203d>;
			};

			pwm2_pins_d: pwm2@3 {
				reg = <3>;
				amb,pinmux-ids = <0x104f>;
			};

			pwm3_pins_a: pwm3@0 {
				reg = <0>;
				amb,pinmux-ids = <0x3005>;
			};

			pwm3_pins_b: pwm3@1 {
				reg = <1>;
				amb,pinmux-ids = <0x302a>;
			};

			pwm3_pins_c: pwm3@2 {
				reg = <2>;
				amb,pinmux-ids = <0x203e>;
			};

			pwm4_pins_a: pwm4@0 {
				reg = <0>;
				amb,pinmux-ids = <0x3006>;
			};

			pwm4_pins_b: pwm4@1 {
				reg = <1>;
				amb,pinmux-ids = <0x302b>;
			};

			pwm4_pins_c: pwm4@2 {
				reg = <2>;
				amb,pinmux-ids = <0x203f>;
			};

			pwm5_pins_a: pwm5@0 {
				reg = <0>;
				amb,pinmux-ids = <0x3007>;
			};

			pwm5_pins_b: pwm5@1 {
				reg = <1>;
				amb,pinmux-ids = <0x302c>;
			};

			pwm5_pins_c: pwm5@2 {
				reg = <2>;
				amb,pinmux-ids = <0x2040>;
			};

			pwm6_pins_a: pwm6@0 {
				reg = <0>;
				amb,pinmux-ids = <0x3008>;
			};

			pwm6_pins_b: pwm6@1 {
				reg = <1>;
				amb,pinmux-ids = <0x302d>;
			};

			pwm6_pins_c: pwm6@2 {
				reg = <2>;
				amb,pinmux-ids = <0x2041>;
			};

			pwm7_pins_a: pwm7@0 {
				reg = <0>;
				amb,pinmux-ids = <0x3009>;
			};

			pwm7_pins_b: pwm7@1 {
				reg = <1>;
				amb,pinmux-ids = <0x302e>;
			};

			pwm7_pins_c: pwm7@2 {
				reg = <2>;
				amb,pinmux-ids = <0x2042>;
			};

			pwm8_pins_a: pwm8@0 {
				reg = <0>;
				amb,pinmux-ids = <0x300a>;
			};

			pwm8_pins_b: pwm8@1 {
				reg = <1>;
				amb,pinmux-ids = <0x302f>;
			};

			pwm8_pins_c: pwm8@2 {
				reg = <2>;
				amb,pinmux-ids = <0x2043>;
			};

			pwm9_pins_a: pwm9@0 {
				reg = <0>;
				amb,pinmux-ids = <0x300b>;
			};

			pwm9_pins_b: pwm9@1 {
				reg = <1>;
				amb,pinmux-ids = <0x3030>;
			};

			pwm9_pins_c: pwm9@2 {
				reg = <2>;
				amb,pinmux-ids = <0x2044>;
			};

			pwm10_pins_a: pwm10@0 {
				reg = <0>;
				amb,pinmux-ids = <0x300c>;
			};

			pwm10_pins_b: pwm10@1 {
				reg = <1>;
				amb,pinmux-ids = <0x3031>;
			};

			pwm10_pins_c: pwm10@2 {
				reg = <2>;
				amb,pinmux-ids = <0x2045>;
			};

			pwm11_pins_a: pwm11@0 {
				reg = <0>;
				amb,pinmux-ids = <0x300d>;
			};

			pwm11_pins_b: pwm11@1 {
				reg = <1>;
				amb,pinmux-ids = <0x3032>;
			};

			pwm11_pins_c: pwm11@2 {
				reg = <2>;
				amb,pinmux-ids = <0x2046>;
			};

			spi0_pins_a: spi0@0 {
				reg = <0>;
				amb,pinmux-ids = <0x1002 0x1003 0x1004>;
			};

			spi0_pins_b: spi0@1 {
				reg = <1>;
				amb,pinmux-ids = <0x3023 0x3024 0x3025>;
			};

			spi0_pins_c: spi0@2 {
				reg = <2>;
				amb,pinmux-ids = <0x20ac 0x20ad 0x20ae>;
			};

			spi1_pins_a: spi1@0 {
				reg = <0>;
				amb,pinmux-ids = <0x1007 0x1008 0x1009>;
			};

			spi1_pins_b: spi1@1 {
				reg = <1>;
				amb,pinmux-ids = <0x20b1 0x20b2 0x20b3>;
			};

			spi2_pins_a: spi2@0 {
				reg = <0>;
				amb,pinmux-ids = <0x100b 0x100c 0x100d>;
			};

			spi2_pins_b: spi2@1 {
				reg = <1>;
				amb,pinmux-ids = <0x3050 0x3051 0x3053>;
			};

			spi2_pins_c: spi2@2 {
				reg = <2>;
				amb,pinmux-ids = <0x20b5 0x20b6 0x20b7>;
			};

			spi3_pins_a: spi3@0 {
				reg = <0>;
				amb,pinmux-ids = <0x100f 0x1010 0x1011>;
			};

			spi3_pins_b: spi3@1 {
				reg = <1>;
				amb,pinmux-ids = <0x3054 0x3055 0x3056>;
			};

			spi3_pins_c: spi3@2 {
				reg = <2>;
				amb,pinmux-ids = <0x20b9 0x20ba 0x20bb>;
			};

			spi4_pins_a: spi4@0 {
				reg = <0>;
				amb,pinmux-ids = <0x1013 0x1014 0x1015>;
			};

			spi4_pins_b: spi4@1 {
				reg = <1>;
				amb,pinmux-ids = <0x20bd 0x20be 0x20bf>;
			};

			spi5_pins: spi5@0 {
				reg = <0>;
				amb,pinmux-ids = <0x1017 0x1018 0x1019>;
			};

			spi6_pins: spi6@0 {
				reg = <0>;
				amb,pinmux-ids = <0x101b 0x101c 0x101d>;
			};

			spi7_pins_a: spi7@0 {
				reg = <0>;
				amb,pinmux-ids = <0x101f 0x1020 0x1021>;
			};

			spi7_pins_b: spi7@1 {
				reg = <1>;
				amb,pinmux-ids = <0x2054 0x2055 0x2056>;
			};

			spi_slave_pins: spi_slave@0 {
				reg = <0>;
				amb,pinmux-ids = <0x1023 0x1024 0x1025 0x1026>;
			};
		};
	};

#if 0
	ca78ae_scratchpad@0xfff0200000 {
		compatible = "simple-bus";
		#address-cells = <1>;
		#size-cells = <1>;
		reg = <0xff 0xf0200000 0x0 0x00010000>;
		ranges = <0xf0200000 0xff 0xf0200000 0x00010000>;

		ca78ae_scratchpad_syscon: ca78ae_scratchpad_syscon@f0200000 {
			compatible = "ambarella,ca78ae-scratchpad", "syscon";
			reg = <0xf0200000 0x10000>;
		};
	};

	hsm {
		compatible = "ambarella,hsm";
		#address-cells = <1>;
		#size-cells = <1>;
		interrupts = <0 28 0x1>, <0 29 0x1>, <0 30 0x1>,
			   <0 425 0x1>, <0 426 0x1>, <0 427 0x1>, <0 428 0x1>;
		interrupt-names = "dram_comm0", "dram_comm1", "dram_comm2",
			"dram_fault_c0", "dram_fault_c1", "dram_fault_c2", "dram_fault_c3";
		domain = "SAFETY";
		scr-regmap = <&ca78ae_scratchpad_syscon>;
		ddrc-regmap = <&ddrc_syscon>;
	};
#endif

	ahb@ffe0000000 {
		compatible = "simple-bus";
		#address-cells = <1>;
		#size-cells = <1>;
		reg = <0xff 0xe0000000 0x0 0x01000000>;
		ranges = <0xe0000000 0xff 0xe0000000 0x01000000>;

		n_scratchpad_syscon: scratchpad_syscon@e003f000 {
			compatible = "ambarella,nsec-scratchpad", "syscon";
			reg = <0xe003f000 0x10000>;
		};

		s_scratchpad_syscon: scratchpad_syscon@e002e000 {
			compatible = "ambarella,sec-scratchpad", "syscon";
			reg = <0xe002e000 0x1000>;
			amb,secure-ctrl-bit = <31>;
		};

		cpuid_syscon: cpuid@e0000000 {
			compatible = "ambarella,cpuid", "syscon";
			reg = <0xe0000000 0x1000>;
		};

		spinor0: spinor@e0001000 {
			compatible = "ambarella,spinor";
			reg = <0xe0001000 0x1000>;
			interrupts = <0 161 0x4>;
			pinctrl-names = "default";
			pinctrl-0 = <&spinor_pins>;
			clocks = <&gclk_ssi3>;
			dmas = <&dma0 31>, <&dma0 32>;
			dma-names = "tx", "rx";
			max-frequency = <50000000>;
			status = "disabled";
		};

		nand0: nand@e0002000 {
			compatible = "ambarella,nand";
			reg = <0xe0002000 0x1000>;
			interrupts = <0 159 0x4>;
			pinctrl-names = "default";
			pinctrl-0 = <&snand_pins>;
			clocks = <&gclk_nand>;
			nand-on-flash-bbt;
			/* amb,soft-ecc = <6>; */
		};

		udc0: udc@e000c000 {
			compatible = "ambarella,udc";
			reg = <0xe000c000 0x2000>;
			interrupts = <0 153 0x4>;
			amb,scr-regmap = <&n_scratchpad_syscon 0x94>;
			amb,usbphy = <&usbphy>;
		};

		dma0: dma@e0020000 {
			compatible = "ambarella,dma";
			reg = <0xe0020000 0x1000>;
			interrupts = <0 175 0x4>;
			#dma-cells = <1>;
			dma-channels = <8>;
			dma-requests = <33>;
			amb,scr-regmap = <&s_scratchpad_syscon 0x2c 0xc4>;
		};

		dma1: dma@e0021000 {
			compatible = "ambarella,dma";
			reg = <0xe0021000 0x1000>;
			interrupts = <0 176 0x4>;
			#dma-cells = <1>;
			dma-channels = <8>;
			dma-requests = <33>;
			amb,scr-regmap = <&s_scratchpad_syscon 0xc8 0xcc>;
		};

		dma2: dma@e0029000 {
			compatible = "ambarella,dma";
			reg = <0xe0029000 0x1000>;
			interrupts = <0 177 0x4>;
			#dma-cells = <1>;
			dma-channels = <8>;
			dma-requests = <33>;
			amb,scr-regmap = <&s_scratchpad_syscon 0x24 0x28>;
		};

		gdma0: gdma@e000b000 {
			compatible = "ambarella,gdma";
			reg = <0xe000b000 0x1000>;
			interrupts = <0 128 0x1>;
		};

		gdma1: gdma@e001b000 {
			compatible = "ambarella,gdma";
			reg = <0xe001b000 0x1000>;
			interrupts = <0 129 0x1>;
		};

		gdma2: gdma@e001e000 {
			compatible = "ambarella,gdma";
			reg = <0xe001e000 0x1000>;
			interrupts = <0 130 0x1>;
		};

		gdma3: gdma@e001f000 {
			compatible = "ambarella,gdma";
			reg = <0xe001f000 0x1000>;
			interrupts = <0 131 0x1>;
		};

		i2s0: i2s@e001c000 {
			compatible = "ambarella,i2s";
			#sound-dai-cells = <0>;
			reg = <0xe001c000 0x1000>;
			pinctrl-names = "default";
			pinctrl-0 = <&i2s0_pins>;
			clocks = <&gclk_audio>;
			amb,i2s-channels = <2>;
			amb,default-mclk = <12288000>;
			dmas = <&dma0 19>, <&dma0 20>;
			dma-names = "tx", "rx";
			amb,ws-set;
			amb,clk-au-enable;
			amb,scr-regmap = <&n_scratchpad_syscon 0x110>;
			status = "disabled";
		};

		i2s1: i2s@e001d000 {
			compatible = "ambarella,i2s";
			#sound-dai-cells = <0>;
			reg = <0xe001d000 0x1000>;
			pinctrl-names = "default";
			pinctrl-0 = <&i2s1_pins>;
			clocks = <&gclk_audio2>;
			amb,i2s-channels = <2>;
			amb,default-mclk = <12288000>;
			dmas = <&dma0 21>, <&dma0 22>;
			dma-names = "tx", "rx";
			amb,ws-set;
			amb,clk-au-enable;
			amb,scr-regmap = <&n_scratchpad_syscon 0x110>;
			status = "disabled";
		};

		/* mac version 5.20  */
		mac0: ethernet@e000e000 {
			compatible = "ambarella-dwmac-eqos","snps,dwmac-5.10a","snps,dwmac";
			#address-cells = <1>;
			#size-cells = <0>;
			reg = <0xe000e000 0x2000>;
			interrupt-parent = <&gic>;
			interrupts = <0 123 0x4>,<0 122 0x4>,<0 119 0x4>;
			interrupt-names="macirq","eth_wake_irq","eth_lpi";

			snps,multicast-filter-bins = <64>;
			snps,perfect-filter-entries = <3>;
			rx-fifo-depth = <8192>;
			tx-fifo-depth = <16384>;

			clocks = <&gclk_maccsr>, <&osc>;
			clock-names = "stmmaceth","ptp_ref";
			max-speed = <1000>;			/* max_1000M */

			snps,tso;
			snps,pbl=<32>;
			snps,no-pbl-x8;
			snps,fixed-burst;
			/* snps,force_sf_dma_mode;
			 * normal: snps,force_sf_dma_mode;
			 * max-frame-size = <1500>; mtu=1500;
			 * jumbo : snps,force_thresh_dma_mode
			*/

			/* assume maxAVBframe=8192, low/high credit
			 * if this data change also modify low/high credit
			 * if AVB used
			*/
			max-frame-size = <8192>;
			snps,axi-config = <&stmmac_axi_setup>;
			snps,mtl-rx-config = <&mtl_rx_setup>;
			snps,mtl-tx-config = <&mtl_tx_setup>;

			/* use MAC-internal mdio-ops and
			 * must delete amb,ahb-12mhz-div = <5>;
			 * clk_csr = 7; mdio_clk=mac_clk_csr/324;
			 * mac_clk_csr = gclk_core and gclk_core/2
			 * check RCT[0x34].periph_clock_mode
			*/
			clk_csr =<7>;
			amb,tx-clk-invert;
			amb,rct-regmap = <&rct_syscon>;
			amb,scr-regmap = <&n_scratchpad_syscon>;
			amb,dma-eame;	/* must ENABLED(CONFIG_ARCH_DMA_ADDR_T_64BIT) to use 40bits dma */
			pinctrl-names = "default";
			pinctrl-0 = <&rgmii0_pins &enet_ext_osc_clk &enet_2nd_ref_clk_c &rgmii0_ptp_pps_o>;
			snps,ps-speed=<1000>;	/* RGMII_SPeed:10/100/1000 base_on enet_ext_osc_clk(2.5M/25M/125M) */
			status = "disabled";
		};

		mac1: ethernet@e0022000 {
			compatible = "ambarella-dwmac-eqos","snps,dwmac-5.10a","snps,dwmac";
			#address-cells = <1>;
			#size-cells = <0>;
			reg = <0xe0022000 0x2000>;
			interrupts = <0 125 0x4>,<0 124 0x4>,<0 120 0x4>;
			interrupt-names="macirq","eth_wake_irq","eth_lpi";
			snps,multicast-filter-bins = <64>;
			snps,perfect-filter-entries = <3>;
			rx-fifo-depth = <8192>;
			tx-fifo-depth = <16384>;
			clocks = <&gclk_maccsr>, <&osc>;
			clock-names = "stmmaceth","ptp_ref";
			max-speed = <1000>;

			snps,tso;
			snps,pbl=<32>;
			snps,no-pbl-x8;
			snps,fixed-burst;
			max-frame-size = <8192>;
			snps,axi-config = <&stmmac_axi_setup>;
			snps,mtl-rx-config = <&mtl_rx_setup>;
			snps,mtl-tx-config = <&mtl_tx_setup>;
			clk_csr =<7>;
			amb,tx-clk-invert;
			amb,rct-regmap = <&rct_syscon>;
			amb,scr-regmap = <&n_scratchpad_syscon>;
			amb,dma-eame;
			pinctrl-names = "default";
			pinctrl-0 = <&rgmii1_pins &rgmii1_ptp_pps_o>;
			snps,ps-speed=<1000>;
			status = "disabled";
		};

		mac2: ethernet@e002a000 {
			compatible = "ambarella-dwmac-eqos","snps,dwmac-5.10a","snps,dwmac";
			#address-cells = <1>;
			#size-cells = <0>;
			reg = <0xe002a000 0x2000>;
			interrupts = <0 127 0x4>,<0 126 0x4>,<0 121 0x4>;
			interrupt-names="macirq","eth_wake_irq","eth_lpi";
			snps,multicast-filter-bins = <64>;
			snps,perfect-filter-entries = <3>;
			rx-fifo-depth = <8192>;
			tx-fifo-depth = <16384>;
			clocks = <&gclk_maccsr>, <&osc>;
			clock-names = "stmmaceth","ptp_ref";
			max-speed = <1000>;

			snps,tso;
			snps,pbl=<32>;
			snps,no-pbl-x8;
			snps,fixed-burst;
			snps,axi-config = <&stmmac_axi_setup>;
			snps,mtl-rx-config = <&mtl_rx_setup>;
			snps,mtl-tx-config = <&mtl_tx_setup>;
			clk_csr =<7>;
			amb,tx-clk-invert;
			amb,rct-regmap = <&rct_syscon>;
			amb,scr-regmap = <&n_scratchpad_syscon>;
			amb,dma-eame;
			pinctrl-names = "default";
			pinctrl-0 = <&rgmii2_pins &rgmii2_ptp_pps_o>;
			snps,ps-speed=<1000>;
			status = "disabled";
		};

		spi0: spi@e0011000 {
			compatible = "ambarella,spi";
			#address-cells = <1>;
			#size-cells = <0>;
			reg = <0xe0011000 0x1000>;
			interrupts = <0 162 0x4>;
			pinctrl-names = "default";
			pinctrl-0 = <&spi0_pins_a>;
			clocks = <&gclk_ssi>;
			/* amb,dma-used; */
			dmas = <&dma0 1>, <&dma0 2>;
			dma-names = "tx", "rx";
			status = "disabled";
		};

		spi1: spi@e0012000 {
			compatible = "ambarella,spi";
			#address-cells = <1>;
			#size-cells = <0>;
			reg = <0xe0012000 0x1000>;
			interrupts = <0 163 0x4>;
			pinctrl-names = "default";
			pinctrl-0 = <&spi1_pins_a>;
			clocks = <&gclk_ssi>;
			/* amb,dma-used; */
			dmas = <&dma0 3>, <&dma0 4>;
			dma-names = "tx", "rx";
			status = "disabled";
		};

		spi2: spi@e0013000 {
			compatible = "ambarella,spi";
			#address-cells = <1>;
			#size-cells = <0>;
			reg = <0xe0013000 0x1000>;
			interrupts = <0 164 0x4>;
			pinctrl-names = "default";
			pinctrl-0 = <&spi2_pins_a>;
			clocks = <&gclk_ssi>;
			/* amb,dma-used; */
			dmas = <&dma1 5>, <&dma1 6>;
			dma-names = "tx", "rx";
			status = "disabled";
		};

		spi3: spi@e0014000 {
			compatible = "ambarella,spi";
			#address-cells = <1>;
			#size-cells = <0>;
			reg = <0xe0014000 0x1000>;
			interrupts = <0 165 0x4>;
			pinctrl-names = "default";
			pinctrl-0 = <&spi3_pins_a>;
			clocks = <&gclk_ssi>;
			/* amb,dma-used; */
			dmas = <&dma1 7>, <&dma1 8>;
			dma-names = "tx", "rx";
			status = "disabled";
		};

		spi4: spi@e0025000 {
			compatible = "ambarella,spi";
			#address-cells = <1>;
			#size-cells = <0>;
			reg = <0xe0025000 0x1000>;
			interrupts = <0 166 0x4>;
			pinctrl-names = "default";
			pinctrl-0 = <&spi4_pins_a>;
			clocks = <&gclk_ssi>;
			/* amb,dma-used; */
			dmas = <&dma1 23>, <&dma1 24>;
			dma-names = "tx", "rx";
			status = "disabled";
		};

		spi5: spi@e0026000 {
			compatible = "ambarella,spi";
			#address-cells = <1>;
			#size-cells = <0>;
			reg = <0xe0026000 0x1000>;
			interrupts = <0 167 0x4>;
			pinctrl-names = "default";
			pinctrl-0 = <&spi5_pins>;
			clocks = <&gclk_ssi>;
			/* amb,dma-used; */
			dmas = <&dma1 25>, <&dma1 26>;
			dma-names = "tx", "rx";
			status = "disabled";
		};

		spi6: spi@e002c000 {
			compatible = "ambarella,spi";
			#address-cells = <1>;
			#size-cells = <0>;
			reg = <0xe002c000 0x1000>;
			interrupts = <0 168 0x4>;
			pinctrl-names = "default";
			pinctrl-0 = <&spi6_pins>;
			clocks = <&gclk_ssi>;
			/* amb,dma-used; */
			dmas = <&dma1 27>, <&dma1 28>;
			dma-names = "tx", "rx";
			status = "disabled";
		};

		spi7: spi@e002d000 {
			compatible = "ambarella,spi";
			#address-cells = <1>;
			#size-cells = <0>;
			reg = <0xe002d000 0x1000>;
			interrupts = <0 169 0x4>;
			pinctrl-names = "default";
			pinctrl-0 = <&spi7_pins_a>;
			clocks = <&gclk_ssi>;
			/* amb,dma-used; */
			dmas = <&dma1 29>, <&dma1 30>;
			dma-names = "tx", "rx";
			status = "disabled";
		};

		spi_slave@e0010000 {
			compatible = "ambarella,spi-slave";
			reg = <0xe0010000 0x1000>;
			interrupts = <0 170 0x4>;
			pinctrl-names = "default";
			pinctrl-0 = <&spi_slave_pins>;
			clocks = <&gclk_ssi2>;
			dmas = <&dma1 9>, <&dma1 10>;
			dma-names = "tx", "rx";
			amb,dma-buf-size = <2048>;
			status = "disabled";
		};

		dmic: dmic@e0015000 {
			compatible = "ambarella,dmic";
			#sound-dai-cells = <0>;
			pinctrl-names = "default";
			pinctrl-0 = <&dmic0_pins>;
			reg = <0xe0015000 0x1000>;
			amb,scr-regmap = <&n_scratchpad_syscon>;
			amb,custom-iir;
			status = "disabled";
		};

		hdmi: hdmi@e0016000 {
			compatible = "ambarella,hdmi";
			reg = <0xe0016000 0x1000>;
			interrupts = <0 127 0x4>;
			interrupt-names = "hdmi";
			vout_id = <2>;
			amb,hdmi-version = <20>;
			amb,phy-regmap = <&rct_syscon 0x7f0 0x7c0 0x7c4>;
			/* phy val : <pib pibib pre_emph post_emph termination bias> */
			amb,hdmi-phy-val-version = <1>;
			amb,hdmi-phy-val-low = <1 3 4 6 0 0>;
			amb,hdmi-phy-val-high = <15 3 2 2 31 2>;
			status = "disabled";
		};

		uart1: uart@e0017000 {	/* UART0_AHB */
			compatible = "ambarella,uart";
			reg = <0xe0017000 0x1000>;
			interrupts = <0 155 0x4>;
			pinctrl-names = "default";
			pinctrl-0 = <&uart1_pins_a &uart1_flow_pins_a>;
			clocks = <&gclk_uart1>;
			amb,msr-used;	/* use Modem Status Register */
			amb,txdma-used;
			amb,rxdma-used;
			dmas = <&dma0 11>, <&dma0 12>;
			dma-names = "tx", "rx";
			status = "disabled";
		};

		uart2: uart@e0018000 { 	/* UART1_AHB */
			compatible = "ambarella,uart";
			reg = <0xe0018000 0x1000>;
			interrupts = <0 156 0x4>;
			pinctrl-names = "default";
			pinctrl-0 = <&uart2_pins_a &uart2_flow_pins_a>;
			clocks = <&gclk_uart2>;
			amb,msr-used;	/* use Modem Status Register */
			amb,txdma-used;
			amb,rxdma-used;
			dmas = <&dma1 13>, <&dma1 14>;
			dma-names = "tx", "rx";
			status = "disabled";
		};

		uart3: uart@e0019000 { 	/* UART2_AHB */
			compatible = "ambarella,uart";
			reg = <0xe0019000 0x1000>;
			interrupts = <0 157 0x4>;
			pinctrl-names = "default";
			pinctrl-0 = <&uart3_pins_a &uart3_flow_pins_a>;
			clocks = <&gclk_uart3>;
			amb,msr-used;	/* use Modem Status Register */
			amb,txdma-used;
			amb,rxdma-used;
			dmas = <&dma1 15>, <&dma1 16>;
			dma-names = "tx", "rx";
			status = "disabled";
		};

		uart4: uart@e001a000 { /* UART3_AHB */
			compatible = "ambarella,uart";
			reg = <0xe001a000 0x1000>;
			interrupts = <0 158 0x4>;
			pinctrl-names = "default";
			pinctrl-0 = <&uart4_pins_a &uart4_flow_pins_a>;
			clocks = <&gclk_uart4>;
			amb,msr-used;	/* use Modem Status Register */
			amb,txdma-used;
			amb,rxdma-used;
			dmas = <&dma1 17>, <&dma1 18>;
			dma-names = "tx", "rx";
			status = "disabled";
		};

		can0: can@e0027000 {
			compatible = "ambarella,can";
			reg = <0xe0027000 0x1000>;
			interrupts = <0 132 0x4>;
			interrupt-names = "canc0";
			pinctrl-names = "default";
			pinctrl-0 = <&can0_pins_a>;
			clocks = <&gclk_can>;
			status = "disabled";
		};

		can1: can@e0028000 {
			compatible = "ambarella,can";
			reg = <0xe0028000 0x1000>;
			interrupts = <0 133 0x4>;
			interrupt-names = "canc1";
			pinctrl-names = "default";
			pinctrl-0 = <&can1_pins_a>;
			clocks = <&gclk_can>;
			status = "disabled";
		};

		can2: can@e0050000 {
			compatible = "ambarella,can";
			reg = <0xe0050000 0x1000>;
			interrupts = <0 134 0x4>;
			interrupt-names = "canc2";
			pinctrl-names = "default";
			pinctrl-0 = <&can2_pins_a>;
			clocks = <&gclk_can>;
			status = "disabled";
		};

		can3: can@e0051000 {
			compatible = "ambarella,can";
			reg = <0xe0051000 0x1000>;
			interrupts = <0 135 0x4>;
			interrupt-names = "canc3";
			pinctrl-names = "default";
			pinctrl-0 = <&can3_pins_a>;
			clocks = <&gclk_can>;
			status = "disabled";
		};

		can4: can@e0052000 {
			compatible = "ambarella,can";
			reg = <0xe0052000 0x1000>;
			interrupts = <0 136 0x4>;
			interrupt-names = "canc4";
			pinctrl-names = "default";
			pinctrl-0 = <&can4_pins_a>;
			clocks = <&gclk_can>;
			status = "disabled";
		};

		can5: can@e0053000 {
			compatible = "ambarella,can";
			reg = <0xe0053000 0x1000>;
			interrupts = <0 137 0x4>;
			interrupt-names = "canc5";
			pinctrl-names = "default";
			pinctrl-0 = <&can5_pins_a>;
			clocks = <&gclk_can>;
			status = "disabled";
		};

		rng0: rng@e002e000 {
			compatible = "ambarella,hw-rng";
			reg = <0xe002e000 0xe8>;
			amb,rct-regmap = <&rct_syscon>;
			amb,secure-ctrl-bit = <31>;
		};

		rtc0: rtc@e002e000 {
			compatible = "ambarella,rtc";
			reg = <0xe002e000 0x100>;
			amb,secure-ctrl-bit = <31>;
			status = "disabled";
		};
	};

	debug-bus@ffed000000 {
		compatible = "simple-bus";
		#address-cells = <1>;
		#size-cells = <1>;
		reg = <0xff 0xed000000 0x0 0x1000000>;
		ranges = <0xed000000 0xff 0xed000000 0x1000000>;

		ddrh_syscon: ddrh_syscon@ed190000 {
			compatible = "ambarella,ddrh", "syscon";
			reg = <0xed190000 0x1000>;
			amb,secure-ctrl-bit = <87>;
		};

		rct_syscon: rct_syscon@ed080000 {
			compatible = "ambarella,rct", "syscon";
			reg = <0xed080000 0x1000>;
			amb,secure-ctrl-bit = <68>;
/*
			amb,secure-addr-rw = <0xed080000 0x1000>;
			amb,secure-addr-ro = <0xed080000 0x008>, <0xed080034 0x004>,
					    <0xed08008c 0x004>, <0xed0800dc 0x010>,
					    <0xed080100 0x01c>, <0xed080148 0x004>,
					    <0xed080174 0x00c>, <0xed0801f4 0x004>,
					    <0xed080224 0x008>, <0xed080264 0x014>,
					    <0xed0802dc 0x00c>, <0xed0803f8 0x008>,
					    <0xed0804f8 0x004>, <0xed0806e4 0x014>,
					    <0xed08070c 0x008>, <0xed080794 0x004>;
*/
		};

		pwc: pwc@ed0d0000 {
			status = "ok";
			compatible = "ambarella,pwc";
			reg = <0xed0d0000 0x1000>;
			amb,secure-ctrl-bit = <71>; /* From YC: sec-dbg-rtc */
			amb,secure-addr-na = <0xed0d0000 0x40>;
		};
	};

	apb-wdt-bus@ffed000000 {
		compatible = "simple-bus";
		#address-cells = <1>;
		#size-cells = <1>;
		reg = <0xff 0xf4000000 0x0 0x10000>;
		ranges = <0xf4000000 0xff 0xf4000000 0x10000>;

		watchdoghsm: wdt@f4000000 {
			compatible = "ambarella,wdt";
			reg = <0xf4000000 0x1000>;
			/* interrupts = <0 231 0x4>; */
			timeout-sec = <15>;
			clocks = <&osc>;
			amb,rct-regmap = <&rct_syscon>;
			amb,secure-ctrl-bit = <49>;
		};

		watchdog0: wdt@f4001000 {
			compatible = "ambarella,wdt";
			reg = <0xf4001000 0x1000>;
			/* interrupts = <0 232 0x4>; */
			timeout-sec = <15>;
			clocks = <&osc>;
			amb,rct-regmap = <&rct_syscon>;
			amb,secure-ctrl-bit = <116>;
		};

		watchdog1: wdt@f4002000 {
			compatible = "ambarella,wdt";
			reg = <0xf4002000 0x1000>;
			/* interrupts = <0 233 0x4>; */
			timeout-sec = <15>;
			clocks = <&osc>;
			amb,rct-regmap = <&rct_syscon>;
			amb,secure-ctrl-bit = <117>;
		};

		watchdog2: wdt@f4003000 {
			compatible = "ambarella,wdt";
			reg = <0xf4003000 0x1000>;
			/* interrupts = <0 234 0x4>; */
			timeout-sec = <15>;
			clocks = <&osc>;
			amb,rct-regmap = <&rct_syscon>;
			amb,secure-ctrl-bit = <118>;
		};

		watchdog3: wdt@f4004000 {
			compatible = "ambarella,wdt";
			reg = <0xf4004000 0x1000>;
			/* interrupts = <0 235 0x4>; */
			timeout-sec = <15>;
			clocks = <&osc>;
			amb,rct-regmap = <&rct_syscon>;
			amb,secure-ctrl-bit = <119>;
		};

		watchdog4: wdt@f4005000 {
			compatible = "ambarella,wdt";
			reg = <0xf4005000 0x1000>;
			/* interrupts = <0 236 0x4>; */
			timeout-sec = <15>;
			clocks = <&osc>;
			amb,rct-regmap = <&rct_syscon>;
			amb,secure-ctrl-bit = <90>;
		};

		watchdog5: wdt@f4006000 {
			compatible = "ambarella,wdt";
			reg = <0xf4006000 0x1000>;
			/* interrupts = <0 237 0x4>; */
			timeout-sec = <15>;
			clocks = <&osc>;
			amb,rct-regmap = <&rct_syscon>;
			amb,secure-ctrl-bit = <59>;
		};
	};

	voutc {
		compatible = "simple-bus";
		#address-cells = <1>;
		#size-cells = <1>;
		reg-names = "vout_base";
		reg = <0xff 0xed0a0000 0x0 0x10000>;
		ranges = <0x0 0xff 0xed0a0000 0x10000>;

		/* node for voutA(lcd: mipi dsi/csi) controller */
		voutc0 {
			compatible = "ambarella,voutc";
			output-type = "mipi_dsi", "mipi_csi";
			reg-names = "display", "mipi_dsi_cmd";
			reg = <0x300 0x200>, <0xb00 0x18>;
			interrupts = <0 149 0x1>;
			interrupt-names = "vout0";
			rct-regmap = <&rct_syscon>;
			clocks = <&pll_out_vo2>;
		};

		/* node for voutB(lcd: mipi dsi/csi) controller */
		voutc1 {
			compatible = "ambarella,voutc";
			output-type = "mipi_dsi", "mipi_csi";
			reg-names = "display", "mipi_dsi_cmd";
			reg = <0x600 0x200>, <0xe00 0x18>;
			interrupts = <0 150 0x1>;
			interrupt-names = "vout1";
			rct-regmap = <&rct_syscon>;
			clocks = <&pll_out_hdmi>;
		};

		/* node for voutC(tv: hdmi/cvbs) controller */
		voutc2 {
			compatible = "ambarella,voutc";
			output-type = "hdmi";
			reg-names = "display";
			reg = <0xc00 0x200>;
			interrupts = <0 151 0x1>;
			interrupt-names = "vout2";
			rct-regmap = <&rct_syscon>;
			clocks = <&pll_out_hdmi>;
		};
	};

	bogus_bus {
		compatible = "simple-bus";
		#address-cells = <1>;
		#size-cells = <0>;

		dummycodec: codec@0 {
			compatible = "ambarella,dummycodec";
			reg = <0>;
		};

		framebuffer0: framebuffer@0 {
			compatible = "ambarella,fb";
			reg = <0>;
			amb,vout-id = <0>;
			amb,format = "rgb565";
		};

		framebuffer1: framebuffer@1 {
			compatible = "ambarella,fb";
			reg = <1>;
			amb,vout-id = <1>;
			amb,format = "rgb565";
		};

		framebuffer2: framebuffer@2 {
			compatible = "ambarella,fb";
			reg = <2>;
			amb,vout-id = <2>;
			amb,format = "rgb565";
		};
	};

	clocks {
		compatible = "ambarella,clkpll-v1";
		#address-cells = <2>;
		#size-cells = <1>;

		/*
		 * This is a dummy clock, to be used as placeholder on other
		 * mux clocks when corresponding bits in register don't
		 * represent real parent clock.
		 */
		gclk_dummy: gclk_dummy {
			#clock-cells = <0>;
			compatible = "fixed-clock";
			clock-frequency = <0>;
		};

		/*
		 * Fixed 24MHz oscillator inputs to SoC
		 */
		osc: oscillator {
			compatible = "fixed-clock";
			#clock-cells = <0>;
			clock-frequency = <24000000>;
			clock-output-names = "osc";
		};

		gclk_core: gclk-core {
			#clock-cells = <0>;
			compatible = "ambarella,pll-clock";
			clocks = <&osc>;
			clock-output-names = "gclk_core";
			amb,clk-regmap = <&rct_syscon 0x000 0x004 0x100 0x104 0x000 0x000>;
			amb,obsv-id = <0x00>;
		};

		gclk_ahb: gclk-ahb {
			#clock-cells = <0>;
			compatible = "ambarella,fixed-factor-clock";
			clocks = <&gclk_core>;
			clock-output-names = "gclk_ahb";
			clock-mult = <1>;
			clock-div = <2>;
		};

		gclk_apb: gclk-apb {
			#clock-cells = <0>;
			compatible = "ambarella,fixed-factor-clock";
			clocks = <&gclk_core>;
			clock-output-names = "gclk_apb";
			clock-mult = <1>;
			clock-div = <4>;
		};

		gclk_ddr0: gclk-ddr0 {
			#clock-cells = <0>;
			compatible = "ambarella,pll-clock";
			clocks = <&osc>;
			clock-output-names = "gclk_ddr0";
			amb,clk-regmap = <&ddrh_syscon 0x000 0x004 0x008 0x00c 0x000 0x000>;
			amb,fix-divider = <2>;
			amb,obsv-id = <0x02>;
		};

		gclk_cortex: gclk-cortex {
			#clock-cells = <0>;
			compatible = "ambarella,pll-clock";
			clocks = <&osc>;
			clock-output-names = "gclk_cortex";
			amb,clk-regmap = <&rct_syscon 0x264 0x268 0x26c 0x270 0x000 0x000>;
			amb,obsv-id = <0x3a>;
		};

		gclk_dsu: gclk-dsu {
			#clock-cells = <0>;
			compatible = "ambarella,pll-clock";
			clocks = <&osc>;
			clock-output-names = "gclk_dsu";
			amb,clk-regmap = <&rct_syscon 0x814 0x818 0x81c 0x820 0x000 0x000>;
			amb,obsv-id = <0x03>;
		};

		gclk_axi: gclk-axi {
			#clock-cells = <0>;
			compatible = "ambarella,fixed-factor-clock";
			clocks = <&gclk_dsu>;
			clock-output-names = "gclk_axi";
			clock-mult = <1>;
			clock-div = <2>;
		};

		gclk_gpu: gclk-gpu {
			#clock-cells = <0>;
			compatible = "ambarella,pll-clock";
			clocks = <&osc>;
			clock-output-names = "gclk_gpu";
			amb,clk-regmap = <&rct_syscon 0x828 0x82c 0x830 0x834 0x000 0x000>;
			amb,obsv-id = <0x2b>;
		};

		gclk_hsm: gclk-hsm {
			#clock-cells = <0>;
			compatible = "ambarella,pll-clock";
			clocks = <&osc>;
			clock-output-names = "gclk_hsm";
			amb,clk-regmap = <&rct_syscon 0x83c 0x840 0x844 0x848 0x000 0x000>;
			amb,obsv-id = <0x2a>;
		};

		gclk_fma: gclk-fma {
			#clock-cells = <0>;
			compatible = "ambarella,pll-clock";
			clocks = <&osc>;
			clock-output-names = "gclk_fma";
			amb,clk-regmap = <&rct_syscon 0x850 0x854 0x858 0x85c 0x000 0x000>;
			amb,obsv-id = <0x28>;
		};

		gclk_vdsp: gclk-vdsp {
			#clock-cells = <0>;
			compatible = "ambarella,pll-clock";
			clocks = <&osc>;
			clock-output-names = "gclk_vdsp";
			amb,clk-regmap = <&rct_syscon 0x8d4 0x8d8 0x8dc 0x8e0 0x000 0x000>;
			amb,obsv-id = <0x04>;
		};

		gclk_idsp: gclk-idsp {
			#clock-cells = <0>;
			compatible = "ambarella,pll-clock";
			clocks = <&osc>;
			clock-output-names = "gclk_idsp";
			amb,clk-regmap = <&rct_syscon 0x0e4 0x0e8 0x108 0x10c 0x000 0x000>;
			amb,obsv-id = <0x01>;
		};

		gclk_idspv: gclk-idspv {
			#clock-cells = <0>;
			compatible = "ambarella,pll-clock";
			clocks = <&osc>;
			clock-output-names = "gclk_idspv";
			amb,clk-regmap = <&rct_syscon 0x7d8 0x7dc 0x7e0 0x7e4 0x000 0x000>;
			amb,obsv-id = <0x05>;
		};

		gclk_nvp: gclk-nvp {
			#clock-cells = <0>;
			compatible = "ambarella,pll-clock";
			clocks = <&osc>;
			clock-output-names = "gclk_nvp";
			amb,clk-regmap = <&rct_syscon 0x878 0x87c 0x880 0x884 0x000 0x000>;
			amb,obsv-id = <0x20>;
		};

		gclk_gvp: gclk-gvp {
			#clock-cells = <0>;
			compatible = "ambarella,pll-clock";
			clocks = <&osc>;
			clock-output-names = "gclk_gvp";
			amb,clk-regmap = <&rct_syscon 0x88c 0x890 0x894 0x898 0x000 0x000>;
			amb,obsv-id = <0x26>;
		};

		gclk_fex: gclk-fex {
			#clock-cells = <0>;
			compatible = "ambarella,pll-clock";
			clocks = <&osc>;
			clock-output-names = "gclk_fex";
			amb,clk-regmap = <&rct_syscon 0x864 0x868 0x86c 0x870 0x000 0x000>;
			amb,obsv-id = <0x29>;
		};

		gclk_so: gclk-so {
			#clock-cells = <0>;
			compatible = "ambarella,pll-clock";
			clocks = <&osc>;
			clock-output-names = "gclk_so";
			assigned-clocks = <&gclk_so>;
			assigned-clock-rates = <24000000>;
			amb,clk-regmap = <&rct_syscon 0x024 0x028 0x11c 0x120 0x04c 0x030>;
			amb,frac-mode;
			amb,obsv-id = <0x10>;
		};

		gclk_so1: gclk-so1 {
			#clock-cells = <0>;
			compatible = "ambarella,pll-clock";
			clocks = <&osc>;
			clock-output-names = "gclk_so1";
			assigned-clocks = <&gclk_so1>;
			assigned-clock-rates = <24000000>;
			amb,clk-regmap = <&rct_syscon 0x8a0 0x8ac 0x8a4 0x8a8 0x000 0x57c>;
			amb,frac-mode;
			amb,obsv-id = <0x33>;
		};

		gclk_so2: gclk-so2 {
			#clock-cells = <0>;
			compatible = "ambarella,pll-clock";
			clocks = <&osc>;
			clock-output-names = "gclk_so2";
			assigned-clocks = <&gclk_so2>;
			assigned-clock-rates = <24000000>;
			amb,clk-regmap = <&rct_syscon 0x74c 0x758 0x750 0x754 0x000 0x578>;
			amb,frac-mode;
			amb,obsv-id = <0x11>;
		};

		gclk_so3: gclk-so3 {
			#clock-cells = <0>;
			compatible = "ambarella,pll-clock";
			clocks = <&osc>;
			clock-output-names = "gclk_so3";
			assigned-clocks = <&gclk_so3>;
			assigned-clock-rates = <24000000>;
			amb,clk-regmap = <&rct_syscon 0x8b4 0x8c0 0x8b8 0x8bc 0x000 0x580>;
			amb,frac-mode;
			amb,obsv-id = <0x34>;
		};

		pll_out_hdmi: pll-out-hdmi {
			#clock-cells = <0>;
			compatible = "ambarella,pll-hdmi-clock";
			clocks = <&osc>;
			clock-output-names = "pll_out_hdmi";
			assigned-clocks = <&pll_out_hdmi>;
			assigned-clock-rates = <46500000>;
			amb,clk-regmap = <&rct_syscon 0x1a8 0x1ac 0x1b0 0x1b4 0x000 0x000>;
			amb,frac-mode;
			amb,vco-min-mhz = <2976>;  /* in MHz */
			amb,vco-range = <2900 3500 4200 5200 11100>;  /* in MHz */
			amb,ctrl2-val = <0x30520000>;
			amb,ctrl3-val = <0x00088004>;
			amb,obsv-id = <0x08>;
		};

		pll_out_vo2: pll-out-vo2 {
			#clock-cells = <0>;
			compatible = "ambarella,pll-clock";
			clocks = <&osc>;
			clock-output-names = "pll_out_vo2";
			assigned-clocks = <&pll_out_vo2>;
			assigned-clock-rates = <24000000>;
			amb,clk-regmap = <&rct_syscon 0x0c0 0x0c4 0x13c 0x140 0x0c8 0x000>;
			amb,frac-mode;
			amb,vco-max-mhz = <1800>;
			amb,obsv-id = <0x09>;
		};

		gclk_audio: gclk-audio {
			#clock-cells = <0>;
			compatible = "ambarella,pll-clock";
			clocks = <&osc>;
			clock-output-names = "gclk_audio";
			assigned-clocks = <&gclk_audio>;
			assigned-clock-rates = <12288000>;
			amb,clk-regmap = <&rct_syscon 0x054 0x058 0x124 0x12c 0x060 0x05c>;
			amb,frac-mode;
			amb,obsv-id = <0x0b>;
		};

		gclk_audio2: gclk-audio2 {
			#clock-cells = <0>;
			compatible = "ambarella,pll-clock";
			clocks = <&osc>;
			clock-output-names = "gclk_audio2";
			assigned-clocks = <&gclk_audio2>;
			assigned-clock-rates = <12288000>;
			amb,clk-regmap = <&rct_syscon 0x054 0x058 0x124 0x12c 0x060 0x600>;
			amb,frac-mode;
			amb,obsv-id = <0x0b>;
		};

		gclk_audio3: gclk-audio3 {
			#clock-cells = <0>;
			compatible = "ambarella,pll-clock";
			clocks = <&osc>;
			clock-output-names = "gclk_audio3";
			assigned-clocks = <&gclk_audio3>;
			assigned-clock-rates = <12288000>;
			amb,clk-regmap = <&rct_syscon 0x054 0x058 0x124 0x12c 0x060 0x604>;
			amb,frac-mode;
			amb,obsv-id = <0x0b>;
		};

		pll_out_sd: pll-out-sd {
			#clock-cells = <0>;
			compatible = "ambarella,pll-clock";
			clocks = <&osc>;
			clock-output-names = "pll_out_sd";
			amb,clk-regmap = <&rct_syscon 0x4ac 0x4b0 0x4b4 0x4b8 0x000 0x000>;
			amb,obsv-id = <0x0c>;
		};

		gclk_sd0: gclk-sd {
			#clock-cells = <0>;
			compatible = "ambarella,composite-clock";
			clocks = <&pll_out_sd>, <&gclk_core>;
			clock-output-names = "gclk_sd0";
			assigned-clocks = <&gclk_sd0>;
			assigned-clock-parents = <&pll_out_sd>;
			amb,div-regmap = <&rct_syscon 0x00c>;
			amb,div-width = <16>;
			amb,div-shift = <0>;
			amb,mux-regmap = <&rct_syscon 0x4d0>;
			amb,mux-mask = <1>;
			amb,mux-shift = <0>;
		};

		gclk_sd1: gclk-sdio0 {
			#clock-cells = <0>;
			compatible = "ambarella,composite-clock";
			clocks = <&pll_out_sd>, <&gclk_core>;
			clock-output-names = "gclk_sd1";
			assigned-clocks = <&gclk_sd1>;
			assigned-clock-parents = <&pll_out_sd>;
			amb,div-regmap = <&rct_syscon 0x430>;
			amb,div-width = <16>;
			amb,div-shift = <0>;
			amb,mux-regmap = <&rct_syscon 0x4d0>;
			amb,mux-mask = <1>;
			amb,mux-shift = <2>;
		};

		gclk_sd2: gclk-sdio1 {
			#clock-cells = <0>;
			compatible = "ambarella,composite-clock";
			clocks = <&pll_out_sd>, <&gclk_core>;
			clock-output-names = "gclk_sd2";
			assigned-clocks = <&gclk_sd2>;
			assigned-clock-parents = <&pll_out_sd>;
			amb,div-regmap = <&rct_syscon 0x434>;
			amb,div-width = <16>;
			amb,div-shift = <0>;
			amb,mux-regmap = <&rct_syscon 0x4d0>;
			amb,mux-mask = <1>;
			amb,mux-shift = <3>;
		};

		gclk_nand: gclk-nand {
			#clock-cells = <0>;
			compatible = "ambarella,pll-clock";
			clocks = <&osc>;
			clock-output-names = "gclk_nand";
			assigned-clocks = <&gclk_nand>;
			assigned-clock-rates = <504000000>;
			amb,clk-regmap = <&rct_syscon 0x6f8 0x6fc 0x700 0x704 0x000 0x000>;
			amb,obsv-id = <0x0e>;
		};

		pll_out_enet: pll-out-enet {
			#clock-cells = <0>;
			compatible = "ambarella,pll-clock";
			clocks = <&osc>;
			clock-output-names = "pll_out_enet";
			amb,clk-regmap = <&rct_syscon 0x520 0x524 0x528 0x52c 0x000 0x000>;
			amb,obsv-id = <0x0d>;
		};

		gclk_uart0: gclk-uart0 {
			#clock-cells = <0>;
			compatible = "ambarella,composite-clock";
			clocks = <&osc>, <&gclk_core>, <&pll_out_enet>, <&pll_out_sd>;
			clock-output-names = "gclk_uart0";
			assigned-clocks = <&gclk_uart0>;
			assigned-clock-parents = <&osc>;
			assigned-clock-rates = <24000000>;
			amb,mux-regmap = <&rct_syscon 0x1c8>;
			amb,div-regmap = <&rct_syscon 0x038>;
			amb,div-width = <24>;
			amb,div-shift = <0>;
		};

		gclk_uart1: gclk-uart1 {
			#clock-cells = <0>;
			compatible = "ambarella,composite-clock";
			clocks = <&osc>, <&gclk_core>, <&pll_out_enet>, <&pll_out_sd>;
			clock-output-names = "gclk_uart1";
			assigned-clocks = <&gclk_uart1>;
			assigned-clock-parents = <&osc>;
			assigned-clock-rates = <24000000>;
			amb,mux-regmap = <&rct_syscon 0x72c>;
			amb,div-regmap = <&rct_syscon 0x714>;
			amb,div-width = <24>;
			amb,div-shift = <0>;
		};

		gclk_uart2: gclk-uart2 {
			#clock-cells = <0>;
			compatible = "ambarella,composite-clock";
			clocks = <&osc>, <&gclk_core>, <&pll_out_enet>, <&pll_out_sd>;
			clock-output-names = "gclk_uart2";
			assigned-clocks = <&gclk_uart2>;
			assigned-clock-parents = <&osc>;
			assigned-clock-rates = <24000000>;
			amb,mux-regmap = <&rct_syscon 0x730>;
			amb,div-regmap = <&rct_syscon 0x718>;
			amb,div-width = <24>;
			amb,div-shift = <0>;
		};

		gclk_uart3: gclk-uart3 {
			#clock-cells = <0>;
			compatible = "ambarella,composite-clock";
			clocks = <&osc>, <&gclk_core>, <&pll_out_enet>, <&pll_out_sd>;
			clock-output-names = "gclk_uart3";
			assigned-clocks = <&gclk_uart3>;
			assigned-clock-parents = <&osc>;
			assigned-clock-rates = <24000000>;
			amb,mux-regmap = <&rct_syscon 0x734>;
			amb,div-regmap = <&rct_syscon 0x71c>;
			amb,div-width = <24>;
			amb,div-shift = <0>;
		};

		gclk_uart4: gclk-uart4 {
			#clock-cells = <0>;
			compatible = "ambarella,composite-clock";
			clocks = <&osc>, <&gclk_core>, <&pll_out_enet>, <&pll_out_sd>;
			clock-output-names = "gclk_uart4";
			assigned-clocks = <&gclk_uart4>;
			assigned-clock-parents = <&osc>;
			assigned-clock-rates = <24000000>;
			amb,mux-regmap = <&rct_syscon 0x738>;
			amb,div-regmap = <&rct_syscon 0x720>;
			amb,div-width = <24>;
			amb,div-shift = <0>;
		};

		gclk_ir: gclk-ir {
			#clock-cells = <0>;
			compatible = "ambarella,div-clock";
			clocks = <&osc>;
			clock-output-names = "gclk_ir";
			amb,div-regmap = <&rct_syscon 0x044>;
			amb,div-width = <24>;
			amb,div-shift = <0>;
		};

		gclk_pwm: gclk-pwm {
			#clock-cells = <0>;
			compatible = "ambarella,composite-clock";
			clocks = <&gclk_apb>, <&gclk_hsm>, <&pll_out_enet>, <&osc>;
			clock-output-names = "gclk_pwm";
			assigned-clocks = <&gclk_pwm>;
			assigned-clock-parents = <&pll_out_enet>;
			amb,mux-regmap = <&rct_syscon 0x1c4>;
			amb,div-regmap = <&rct_syscon 0x084>;
			amb,div-width = <24>;
			amb,div-shift = <0>;
		};

		gclk_ssi: gclk-ssi { /* for SSI master */
			#clock-cells = <0>;
			compatible = "ambarella,div-clock";
			clocks = <&gclk_core>;
			clock-output-names = "gclk_ssi";
			assigned-clocks = <&gclk_ssi>;
			assigned-clock-rates = <54000000>;
			amb,div-regmap = <&rct_syscon 0x03c>;
			amb,div-width = <24>;
			amb,div-shift = <0>;
		};

		gclk_ssi2: gclk-ssi2 { /* for SSI slave */
			#clock-cells = <0>;
			compatible = "ambarella,div-clock";
			clocks = <&gclk_core>;
			clock-output-names = "gclk_ssi2";
			amb,div-regmap = <&rct_syscon 0x0ec>;
			amb,div-width = <24>;
			amb,div-shift = <0>;
		};

		gclk_ssi3: gclk-ssi3 { /* for SPINOR */
			#clock-cells = <0>;
			compatible = "ambarella,composite-clock";
			clocks = <&gclk_nand>, <&gclk_core>, <&gclk_ssi>, <&osc>;
			clock-output-names = "gclk_ssi3";
			amb,mux-regmap = <&rct_syscon 0x51c>;
			amb,div-regmap = <&rct_syscon 0x518>;
			amb,div-width = <24>;
			amb,div-shift = <0>;
		};

		gclk_can: gclk-can {
			#clock-cells = <0>;
			compatible = "ambarella,composite-clock";
			clocks = <&osc>, <&pll_out_enet>, <&gclk_ahb>;
			clock-output-names = "gclk_can";
			assigned-clocks = <&gclk_can>;
			assigned-clock-parents = <&pll_out_enet>;
			amb,mux-regmap = <&rct_syscon 0x56c>;
			amb,div-regmap = <&rct_syscon 0x570>;
			amb,div-width = <8>;
			amb,div-shift = <0>;
		};

		/* Fixed 100MHz for cdns phy {usb3,pcie,pcie-switch} */
		cdns_phy_refclk: cdns-phy-refclk {
			#clock-cells = <0>;
			compatible = "fixed-clock";
			clock-frequency = <100000000>;
			clock-output-names = "cdns-phy-refclk";
		};

		/*
		 * gclk_maccsr = gclk_core/2 (rct.0x34.bit26=0)
		 * or
		 * gclk_maccsr = gclk_core   (rct.0x34.bit26=1)
		 * mac-mdio ops
		 */
		gclk_maccsr: gclk-maccsr {
			#clock-cells = <0>;
			compatible = "ambarella,mux-clock";
			clocks = <&gclk_ahb>, <&gclk_core>;
			clock-output-names = "gclk_maccsr";
			amb,mux-regmap = <&rct_syscon 0x34>;
			amb,mux-mask = <0x1>;
			amb,mux-shift = <26>;
		};
	};
};
